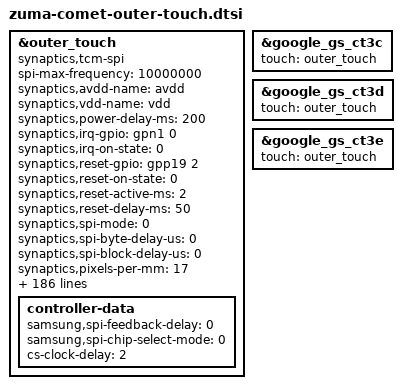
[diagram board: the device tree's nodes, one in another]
// SPDX-License-Identifier: GPL-2.0-only
/*
 * Google Comet touch device tree source
 *
 * Copyright 2023 Google LLC.
 *
 */

#include "zuma-comet-outer-common-touch.dtsi"

&outer_touch {
	status = "ok";
	compatible = "synaptics,tcm-spi";

	spi-max-frequency = <10000000>;

	synaptics,avdd-name = "avdd";
	synaptics,vdd-name = "vdd";
	synaptics,power-delay-ms = <200>;
	synaptics,irq-gpio = <&gpn1 0 0x2008>; /* IRQF_ONESHOT | IRQF_TRIGGER_LOW */
	synaptics,irq-on-state = <0>;
	synaptics,reset-gpio = <&gpp19 2 0>;
	synaptics,reset-on-state = <0>;
	synaptics,reset-active-ms = <2>;
	synaptics,reset-delay-ms = <50>;
	synaptics,spi-mode = <0>;
	synaptics,spi-byte-delay-us = <0>;
	synaptics,spi-block-delay-us = <0>;

	synaptics,pixels-per-mm = <17>;
	synaptics,panel_map = <&google_gs_ct3c 0>,<&google_gs_ct3d 1>,<&google_gs_ct3e 2>;
	synaptics,firmware_names = "synaptics.img","synaptics_b.img","synaptics_c.img";
	synaptics,test_algo = <0 1>;

	goog,panel_map = <&google_gs_ct3c 0>,<&google_gs_ct3d 1>,<&google_gs_ct3e 2>;

	goog,dev-id = <1>;
	goog,offload-device-name = "outer";
	goog,touch_offload_ids = /bits/ 8 <'c' 't' '3' '2' 'c' 't' '3' '3' 'c' 't' '3' '4'>;
	goog,display-resolution = /bits/ 16 <1080 2424>;
	goog,channel-num = /bits/ 16 <16 36>;
	goog,offload-caps-data-types = /bits/ 16 <0x1F>;
	goog,offload-caps-scan-types = /bits/ 16 <0xC0>;
	goog,offload-caps-context-channel-types = /bits/ 16 <0x0100>;
	goog,offload-caps-coord-filter;
	goog,tbn-enabled;
	goog,manual-heatmap-from-irq;
	goog,v4l2-enabled;
	goog,offload-enabled;
	goog,coord-filter-enabled;
	goog,reset-after-selftest;

	synaptics,pt05_high_name = "synaptics,pt05_high","synaptics,pt05_high_b",
			"synaptics,pt05_high_c";
	synaptics,pt05_low_name = "synaptics,pt05_low","synaptics,pt05_low_b",
			"synaptics,pt05_low_c";
	synaptics,pt05_gap_x_name = "synaptics,pt05_gap_x","synaptics,pt05_gap_x_b",
			"synaptics,pt05_gap_x_c";
	synaptics,pt05_gap_y_name = "synaptics,pt05_gap_y","synaptics,pt05_gap_y_b",
			"synaptics,pt05_gap_y_c";
	synaptics,pt0a_high_name = "synaptics,pt0a_high","synaptics,pt0a_high_b",
			"synaptics,pt0a_high_c";
	synaptics,pt0a_low_name = "synaptics,pt0a_low","synaptics,pt0a_low_b",
			"synaptics,pt0a_low_c";
	synaptics,pt10_high_name = "synaptics,pt10_high","synaptics,pt10_high_b",
			"synaptics,pt10_high_c";
	synaptics,pt10_low_name = "synaptics,pt10_low","synaptics,pt10_low_b",
			"synaptics,pt10_low_c";
	synaptics,pt10_gap_x_name = "synaptics,pt10_gap_x","synaptics,pt10_gap_x_b",
			"synaptics,pt10_gap_x_c";
	synaptics,pt10_gap_y_name = "synaptics,pt10_gap_y","synaptics,pt10_gap_y_b",
			"synaptics,pt10_gap_y_c";
	synaptics,pt11_high_name = "synaptics,pt11_high","synaptics,pt11_high_b",
			"synaptics,pt11_high";
	synaptics,pt11_low_name = "synaptics,pt11_low","synaptics,pt11_low_b",
			"synaptics,pt11_low_c";
	synaptics,pt12_high_name = "synaptics,pt12_high","synaptics,pt12_high_b",
			"synaptics,pt12_high_c";
	synaptics,pt12_low_name = "synaptics,pt12_low","synaptics,pt12_low_b",
			"synaptics,pt12_low_c";
	synaptics,pt16_high_name = "synaptics,pt16_high","synaptics,pt16_high_b",
			"synaptics,pt16_high_c";
	synaptics,pt16_low_name = "synaptics,pt16_low","synaptics,pt16_low_b",
			"synaptics,pt16_low_c";
	synaptics,pt_tag_moisture_name = "synaptics,pt_tag_moisture",
			"synaptics,pt_tag_moisture_b",
			"synaptics,pt_tag_moisture_c";

	synaptics,pt05_high = /bits/ 16 <
850 850 850 850 850 850 850 850 850 850 850 850 850 850 850 850 850 850 850 850 850 850 850 850 850 850 850 850 850 850 850 850 850 850 850 850
850 850 850 850 850 850 850 850 850 850 850 850 850 850 850 850 850 850 850 850 850 850 850 850 850 850 850 850 850 850 850 850 850 850 850 850
850 850 850 850 850 850 850 850 850 850 850 850 850 850 850 850 850 850 850 850 850 850 850 850 850 850 850 850 850 850 850 850 850 850 850 850
850 850 850 850 850 850 850 850 850 850 850 850 850 850 850 850 850 850 850 850 850 850 850 850 850 850 850 850 850 850 850 850 850 850 850 850
850 850 850 850 850 850 850 850 850 850 850 850 850 850 850 850 850 850 850 850 850 850 850 850 850 850 850 850 850 850 850 850 850 850 850 850
850 850 850 850 850 850 850 850 850 850 850 850 850 850 850 850 850 850 850 850 850 850 850 850 850 850 850 850 850 850 850 850 850 850 850 850
850 850 850 850 850 850 850 850 850 850 850 850 850 850 850 850 850 850 850 850 850 850 850 850 850 850 850 850 850 850 850 850 850 850 850 850
850 850 850 850 850 850 850 850 850 850 850 850 850 850 850 850 850 850 850 850 850 850 850 850 850 850 850 850 850 850 850 850 850 850 850 850
850 850 850 850 850 850 850 850 850 850 850 850 850 850 850 850 850 850 850 850 850 850 850 850 850 850 850 850 850 850 850 850 850 850 850 850
850 850 850 850 850 850 850 850 850 850 850 850 850 850 850 850 850 850 850 850 850 850 850 850 850 850 850 850 850 850 850 850 850 850 850 850
850 850 850 850 850 850 850 850 850 850 850 850 850 850 850 850 850 850 850 850 850 850 850 850 850 850 850 850 850 850 850 850 850 850 850 850
850 850 850 850 850 850 850 850 850 850 850 850 850 850 850 850 850 850 850 850 850 850 850 850 850 850 850 850 850 850 850 850 850 850 850 850
850 850 850 850 850 850 850 850 850 850 850 850 850 850 850 850 850 850 850 850 850 850 850 850 850 850 850 850 850 850 850 850 850 850 850 850
850 850 850 850 850 850 850 850 850 850 850 850 850 850 850 850 850 850 850 850 850 850 850 850 850 850 850 850 850 850 850 850 850 850 850 850
850 850 850 850 850 850 850 850 850 850 850 850 850 850 850 850 850 850 850 850 850 850 850 850 850 850 850 850 850 850 850 850 850 850 850 850
850 850 850 850 850 850 850 850 850 850 850 850 850 850 850 850 850 850 850 850 850 850 850 850 850 850 850 850 850 850 850 850 850 850 850 850>;
	synaptics,pt05_low = /bits/ 16 <
80 100 100 100 100 100 100 100 100 100 100 100 100 100 100 100 100 100 100 100 100 100 100 100 100 100 100 100 100 100 100 100 100 100 100 15
100 100 100 100 100 100 100 100 100 100 100 100 100 100 100 100 100 100 100 100 100 100 100 100 100 100 100 100 100 100 100 100 100 100 100 100
100 100 100 100 100 100 100 100 100 100 100 100 100 100 100 100 100 100 100 100 100 100 100 100 100 100 100 100 100 100 100 100 100 100 100 100
100 100 100 100 100 100 100 100 100 100 100 100 100 100 100 100 100 100 100 100 100 100 100 100 100 100 100 100 100 100 100 100 100 100 100 100
100 100 100 100 100 100 100 100 100 100 100 100 100 100 100 100 100 100 100 100 100 100 100 100 100 100 100 100 100 100 100 100 100 100 100 100
100 100 100 100 100 100 100 100 100 100 100 100 100 100 100 100 100 100 100 100 100 100 100 100 100 100 100 100 100 100 100 100 100 100 100 100
100 100 100 100 100 100 100 100 100 100 100 100 100 100 100 100 100 100 100 100 100 100 100 100 100 100 100 100 100 100 100 100 100 100 100 100
100 100 100 100 100 100 100 100 100 100 100 100 100 100 100 100 100 100 100 100 100 100 100 100 100 100 100 100 100 100 100 100 100 100 100 100
100 100 100 100 100 100 100 100 100 100 100 100 100 100 100 100 100 100 100 100 100 100 100 100 100 100 100 100 100 100 100 100 100 100 100 100
100 100 100 100 100 100 100 100 100 100 100 100 100 100 100 100 100 100 100 100 100 100 100 100 100 100 100 100 100 100 100 100 100 100 100 100
100 100 100 100 100 100 100 100 100 100 100 100 100 100 100 100 100 100 100 100 100 100 100 100 100 100 100 100 100 100 100 100 100 100 100 100
100 100 100 100 100 100 100 100 100 100 100 100 100 100 100 100 100 100 100 100 100 100 100 100 100 100 100 100 100 100 100 100 100 100 100 100
100 100 100 100 100 100 100 100 100 100 100 100 100 100 100 100 100 100 100 100 100 100 100 100 100 100 100 100 100 100 100 100 100 100 100 100
100 100 100 100 100 100 100 100 100 100 100 100 100 100 100 100 100 100 100 100 100 100 100 100 100 100 100 100 100 100 100 100 100 100 100 100
100 100 100 100 100 100 100 100 100 100 100 100 100 100 100 100 100 100 100 100 100 100 100 100 100 100 100 100 100 100 100 100 100 100 100 100
15 100 100 100 100 100 100 100 100 100 100 100 100 100 100 100 100 100 100 100 100 100 100 100 100 100 100 100 100 100 100 100 100 100 100 80>;
	synaptics,pt05_gap_x = /bits/ 16 <
97 60 40 40 40 40 40 40 40 40 40 40 40 40 40 40 40 40 40 40 40 40 40 40 40 40 40 40 40 40 40 40 40 40 97 97
60 40 40 40 40 40 40 40 40 40 40 40 40 40 40 40 40 40 40 40 40 40 40 40 40 40 40 40 40 40 40 40 40 40 50 60
40 40 40 40 40 40 40 40 40 40 40 40 40 40 40 40 40 40 40 40 40 40 40 40 40 40 40 40 40 40 40 40 40 40 50 40
40 40 40 40 40 40 40 40 40 40 40 40 40 40 40 40 40 40 40 40 40 40 40 40 40 40 40 40 40 40 40 40 40 40 50 40
40 40 40 40 40 40 40 40 40 40 40 40 40 40 40 40 40 40 40 40 40 40 40 40 40 40 40 40 40 40 40 40 40 40 50 40
40 40 40 40 40 40 40 40 40 40 40 40 40 40 40 40 40 40 40 40 40 40 40 40 40 40 40 40 40 40 40 40 40 40 50 40
40 55 40 40 40 40 40 40 40 40 40 40 40 40 40 40 40 40 40 40 40 40 40 40 40 40 40 40 40 40 40 40 40 40 50 40
55 55 40 40 40 40 40 40 40 40 40 40 40 40 40 40 40 40 40 40 40 40 40 40 40 40 40 40 40 40 40 40 40 40 50 40
55 55 40 40 40 40 40 40 40 40 40 40 40 40 40 40 40 40 40 40 40 40 40 40 40 40 40 40 40 40 40 40 40 40 50 40
40 40 40 40 40 40 40 40 40 40 40 40 40 40 40 40 40 40 40 40 40 40 40 40 40 40 40 40 40 40 40 40 40 40 50 40
40 40 40 40 40 40 40 40 40 40 40 40 40 40 40 40 40 40 40 40 40 40 40 40 40 40 40 40 40 40 40 40 40 40 50 40
40 40 40 40 40 40 40 40 40 40 40 40 40 40 40 40 40 40 40 40 40 40 40 40 40 40 40 40 40 40 40 40 40 40 50 40
40 40 40 40 40 40 40 40 40 40 40 40 40 40 40 40 40 40 40 40 40 40 40 40 40 40 40 40 40 40 40 40 40 40 50 40
60 40 40 40 40 40 40 40 40 40 40 40 40 40 40 40 40 40 40 40 40 40 40 40 40 40 40 40 40 40 40 40 40 40 50 60
97 60 40 40 40 40 40 40 40 40 40 40 40 40 40 40 40 40 40 40 40 40 40 40 40 40 40 40 40 40 40 40 40 40 60 60
97 60 40 40 40 40 40 40 40 40 40 40 40 40 40 40 40 40 40 40 40 40 40 40 40 40 40 40 40 40 40 40 40 40 97 40>;

	synaptics,pt0a_high = /bits/ 16 <
50 50 50 50 50 50 50 50 50 50 50 50 50 50 50 50 50 50 50 50 50 50 50 50 50 50 50 50 50 50 50 50 50 50 50 50
50 50 50 50 50 50 50 50 50 50 50 50 50 50 50 50 50 50 50 50 50 50 50 50 50 50 50 50 50 50 50 50 50 50 50 50
50 50 50 50 50 50 50 50 50 50 50 50 50 50 50 50 50 50 50 50 50 50 50 50 50 50 50 50 50 50 50 50 50 50 50 50
50 50 50 50 50 50 50 50 50 50 50 50 50 50 50 50 50 50 50 50 50 50 50 50 50 50 50 50 50 50 50 50 50 50 50 50
50 50 50 50 50 50 50 50 50 50 50 50 50 50 50 50 50 50 50 50 50 50 50 50 50 50 50 50 50 50 50 50 50 50 50 50
50 50 50 50 50 50 50 50 50 50 50 50 50 50 50 50 50 50 50 50 50 50 50 50 50 50 50 50 50 50 50 50 50 50 50 50
50 50 50 50 50 50 50 50 50 50 50 50 50 50 50 50 50 50 50 50 50 50 50 50 50 50 50 50 50 50 50 50 50 50 50 50
50 50 50 50 50 50 50 50 50 50 50 50 50 50 50 50 50 50 50 50 50 50 50 50 50 50 50 50 50 50 50 50 50 50 50 50
50 50 50 50 50 50 50 50 50 50 50 50 50 50 50 50 50 50 50 50 50 50 50 50 50 50 50 50 50 50 50 50 50 50 50 50
50 50 50 50 50 50 50 50 50 50 50 50 50 50 50 50 50 50 50 50 50 50 50 50 50 50 50 50 50 50 50 50 50 50 50 50
50 50 50 50 50 50 50 50 50 50 50 50 50 50 50 50 50 50 50 50 50 50 50 50 50 50 50 50 50 50 50 50 50 50 50 50
50 50 50 50 50 50 50 50 50 50 50 50 50 50 50 50 50 50 50 50 50 50 50 50 50 50 50 50 50 50 50 50 50 50 50 50
50 50 50 50 50 50 50 50 50 50 50 50 50 50 50 50 50 50 50 50 50 50 50 50 50 50 50 50 50 50 50 50 50 50 50 50
50 50 50 50 50 50 50 50 50 50 50 50 50 50 50 50 50 50 50 50 50 50 50 50 50 50 50 50 50 50 50 50 50 50 50 50
50 50 50 50 50 50 50 50 50 50 50 50 50 50 50 50 50 50 50 50 50 50 50 50 50 50 50 50 50 50 50 50 50 50 50 50
50 50 50 50 50 50 50 50 50 50 50 50 50 50 50 50 50 50 50 50 50 50 50 50 50 50 50 50 50 50 50 50 50 50 50 50>;
	synaptics,pt0a_low = /bits/ 16 <
(-50) (-50) (-50) (-50) (-50) (-50) (-50) (-50) (-50) (-50) (-50) (-50) (-50) (-50) (-50) (-50) (-50) (-50) (-50) (-50) (-50) (-50) (-50) (-50) (-50) (-50) (-50) (-50) (-50) (-50) (-50) (-50) (-50) (-50) (-50) (-50)
(-50) (-50) (-50) (-50) (-50) (-50) (-50) (-50) (-50) (-50) (-50) (-50) (-50) (-50) (-50) (-50) (-50) (-50) (-50) (-50) (-50) (-50) (-50) (-50) (-50) (-50) (-50) (-50) (-50) (-50) (-50) (-50) (-50) (-50) (-50) (-50)
(-50) (-50) (-50) (-50) (-50) (-50) (-50) (-50) (-50) (-50) (-50) (-50) (-50) (-50) (-50) (-50) (-50) (-50) (-50) (-50) (-50) (-50) (-50) (-50) (-50) (-50) (-50) (-50) (-50) (-50) (-50) (-50) (-50) (-50) (-50) (-50)
(-50) (-50) (-50) (-50) (-50) (-50) (-50) (-50) (-50) (-50) (-50) (-50) (-50) (-50) (-50) (-50) (-50) (-50) (-50) (-50) (-50) (-50) (-50) (-50) (-50) (-50) (-50) (-50) (-50) (-50) (-50) (-50) (-50) (-50) (-50) (-50)
(-50) (-50) (-50) (-50) (-50) (-50) (-50) (-50) (-50) (-50) (-50) (-50) (-50) (-50) (-50) (-50) (-50) (-50) (-50) (-50) (-50) (-50) (-50) (-50) (-50) (-50) (-50) (-50) (-50) (-50) (-50) (-50) (-50) (-50) (-50) (-50)
(-50) (-50) (-50) (-50) (-50) (-50) (-50) (-50) (-50) (-50) (-50) (-50) (-50) (-50) (-50) (-50) (-50) (-50) (-50) (-50) (-50) (-50) (-50) (-50) (-50) (-50) (-50) (-50) (-50) (-50) (-50) (-50) (-50) (-50) (-50) (-50)
(-50) (-50) (-50) (-50) (-50) (-50) (-50) (-50) (-50) (-50) (-50) (-50) (-50) (-50) (-50) (-50) (-50) (-50) (-50) (-50) (-50) (-50) (-50) (-50) (-50) (-50) (-50) (-50) (-50) (-50) (-50) (-50) (-50) (-50) (-50) (-50)
(-50) (-50) (-50) (-50) (-50) (-50) (-50) (-50) (-50) (-50) (-50) (-50) (-50) (-50) (-50) (-50) (-50) (-50) (-50) (-50) (-50) (-50) (-50) (-50) (-50) (-50) (-50) (-50) (-50) (-50) (-50) (-50) (-50) (-50) (-50) (-50)
(-50) (-50) (-50) (-50) (-50) (-50) (-50) (-50) (-50) (-50) (-50) (-50) (-50) (-50) (-50) (-50) (-50) (-50) (-50) (-50) (-50) (-50) (-50) (-50) (-50) (-50) (-50) (-50) (-50) (-50) (-50) (-50) (-50) (-50) (-50) (-50)
(-50) (-50) (-50) (-50) (-50) (-50) (-50) (-50) (-50) (-50) (-50) (-50) (-50) (-50) (-50) (-50) (-50) (-50) (-50) (-50) (-50) (-50) (-50) (-50) (-50) (-50) (-50) (-50) (-50) (-50) (-50) (-50) (-50) (-50) (-50) (-50)
(-50) (-50) (-50) (-50) (-50) (-50) (-50) (-50) (-50) (-50) (-50) (-50) (-50) (-50) (-50) (-50) (-50) (-50) (-50) (-50) (-50) (-50) (-50) (-50) (-50) (-50) (-50) (-50) (-50) (-50) (-50) (-50) (-50) (-50) (-50) (-50)
(-50) (-50) (-50) (-50) (-50) (-50) (-50) (-50) (-50) (-50) (-50) (-50) (-50) (-50) (-50) (-50) (-50) (-50) (-50) (-50) (-50) (-50) (-50) (-50) (-50) (-50) (-50) (-50) (-50) (-50) (-50) (-50) (-50) (-50) (-50) (-50)
(-50) (-50) (-50) (-50) (-50) (-50) (-50) (-50) (-50) (-50) (-50) (-50) (-50) (-50) (-50) (-50) (-50) (-50) (-50) (-50) (-50) (-50) (-50) (-50) (-50) (-50) (-50) (-50) (-50) (-50) (-50) (-50) (-50) (-50) (-50) (-50)
(-50) (-50) (-50) (-50) (-50) (-50) (-50) (-50) (-50) (-50) (-50) (-50) (-50) (-50) (-50) (-50) (-50) (-50) (-50) (-50) (-50) (-50) (-50) (-50) (-50) (-50) (-50) (-50) (-50) (-50) (-50) (-50) (-50) (-50) (-50) (-50)
(-50) (-50) (-50) (-50) (-50) (-50) (-50) (-50) (-50) (-50) (-50) (-50) (-50) (-50) (-50) (-50) (-50) (-50) (-50) (-50) (-50) (-50) (-50) (-50) (-50) (-50) (-50) (-50) (-50) (-50) (-50) (-50) (-50) (-50) (-50) (-50)
(-50) (-50) (-50) (-50) (-50) (-50) (-50) (-50) (-50) (-50) (-50) (-50) (-50) (-50) (-50) (-50) (-50) (-50) (-50) (-50) (-50) (-50) (-50) (-50) (-50) (-50) (-50) (-50) (-50) (-50) (-50) (-50) (-50) (-50) (-50) (-50)>;

	synaptics,pt10_high = /bits/ 16 <
55 55 55 55 55 55 55 55 55 55 55 55 55 55 55 55 55 55 55 55 55 55 55 55 55 55 55 55 55 55 55 55 55 55 55 55
55 55 55 55 55 55 55 55 55 55 55 55 55 55 55 55 55 55 55 55 55 55 55 55 55 55 55 55 55 55 55 55 55 55 55 55
55 55 55 55 55 55 55 55 55 55 55 55 55 55 55 55 55 55 55 55 55 55 55 55 55 55 55 55 55 55 55 55 55 55 55 55
55 55 55 55 55 55 55 55 55 55 55 55 55 55 55 55 55 55 55 55 55 55 55 55 55 55 55 55 55 55 55 55 55 55 55 55
55 55 55 55 55 55 55 55 55 55 55 55 55 55 55 55 55 55 55 55 55 55 55 55 55 55 55 55 55 55 55 55 55 55 55 55
55 55 55 55 55 55 55 55 55 55 55 55 55 55 55 55 55 55 55 55 55 55 55 55 55 55 55 55 55 55 55 55 55 55 55 55
55 55 55 55 55 55 55 55 55 55 55 55 55 55 55 55 55 55 55 55 55 55 55 55 55 55 55 55 55 55 55 55 55 55 55 55
55 55 55 55 55 55 55 55 55 55 55 55 55 55 55 55 55 55 55 55 55 55 55 55 55 55 55 55 55 55 55 55 55 55 55 55
55 55 55 55 55 55 55 55 55 55 55 55 55 55 55 55 55 55 55 55 55 55 55 55 55 55 55 55 55 55 55 55 55 55 55 55
55 55 55 55 55 55 55 55 55 55 55 55 55 55 55 55 55 55 55 55 55 55 55 55 55 55 55 55 55 55 55 55 55 55 55 55
55 55 55 55 55 55 55 55 55 55 55 55 55 55 55 55 55 55 55 55 55 55 55 55 55 55 55 55 55 55 55 55 55 55 55 55
55 55 55 55 55 55 55 55 55 55 55 55 55 55 55 55 55 55 55 55 55 55 55 55 55 55 55 55 55 55 55 55 55 55 55 55
55 55 55 55 55 55 55 55 55 55 55 55 55 55 55 55 55 55 55 55 55 55 55 55 55 55 55 55 55 55 55 55 55 55 55 55
55 55 55 55 55 55 55 55 55 55 55 55 55 55 55 55 55 55 55 55 55 55 55 55 55 55 55 55 55 55 55 55 55 55 55 55
55 55 55 55 55 55 55 55 55 55 55 55 55 55 55 55 55 55 55 55 55 55 55 55 55 55 55 55 55 55 55 55 55 55 55 55
55 55 55 55 55 55 55 55 55 55 55 55 55 55 55 55 55 55 55 55 55 55 55 55 55 55 55 55 55 55 55 55 55 55 55 55>;
	synaptics,pt10_low = /bits/ 16 <
0 0 0 0 0 0 0 0 0 0 0 0 0 0 0 0 0 0 0 0 0 0 0 0 0 0 0 0 0 0 0 0 0 0 0 0
0 0 0 0 0 0 0 0 0 0 0 0 0 0 0 0 0 0 0 0 0 0 0 0 0 0 0 0 0 0 0 0 0 0 0 0
0 0 0 0 0 0 0 0 0 0 0 0 0 0 0 0 0 0 0 0 0 0 0 0 0 0 0 0 0 0 0 0 0 0 0 0
0 0 0 0 0 0 0 0 0 0 0 0 0 0 0 0 0 0 0 0 0 0 0 0 0 0 0 0 0 0 0 0 0 0 0 0
0 0 0 0 0 0 0 0 0 0 0 0 0 0 0 0 0 0 0 0 0 0 0 0 0 0 0 0 0 0 0 0 0 0 0 0
0 0 0 0 0 0 0 0 0 0 0 0 0 0 0 0 0 0 0 0 0 0 0 0 0 0 0 0 0 0 0 0 0 0 0 0
0 0 0 0 0 0 0 0 0 0 0 0 0 0 0 0 0 0 0 0 0 0 0 0 0 0 0 0 0 0 0 0 0 0 0 0
0 0 0 0 0 0 0 0 0 0 0 0 0 0 0 0 0 0 0 0 0 0 0 0 0 0 0 0 0 0 0 0 0 0 0 0
0 0 0 0 0 0 0 0 0 0 0 0 0 0 0 0 0 0 0 0 0 0 0 0 0 0 0 0 0 0 0 0 0 0 0 0
0 0 0 0 0 0 0 0 0 0 0 0 0 0 0 0 0 0 0 0 0 0 0 0 0 0 0 0 0 0 0 0 0 0 0 0
0 0 0 0 0 0 0 0 0 0 0 0 0 0 0 0 0 0 0 0 0 0 0 0 0 0 0 0 0 0 0 0 0 0 0 0
0 0 0 0 0 0 0 0 0 0 0 0 0 0 0 0 0 0 0 0 0 0 0 0 0 0 0 0 0 0 0 0 0 0 0 0
0 0 0 0 0 0 0 0 0 0 0 0 0 0 0 0 0 0 0 0 0 0 0 0 0 0 0 0 0 0 0 0 0 0 0 0
0 0 0 0 0 0 0 0 0 0 0 0 0 0 0 0 0 0 0 0 0 0 0 0 0 0 0 0 0 0 0 0 0 0 0 0
0 0 0 0 0 0 0 0 0 0 0 0 0 0 0 0 0 0 0 0 0 0 0 0 0 0 0 0 0 0 0 0 0 0 0 0
0 0 0 0 0 0 0 0 0 0 0 0 0 0 0 0 0 0 0 0 0 0 0 0 0 0 0 0 0 0 0 0 0 0 0 0>;
	synaptics,pt10_gap_x = /bits/ 16 <
50 50 50 50 50 50 50 50 50 50 50 50 50 50 50 50 50 50 50 50 50 50 50 50 50 50 50 50 50 50 50 50 50 50 50 50
50 50 50 50 50 50 50 50 50 50 50 50 50 50 50 50 50 50 50 50 50 50 50 50 50 50 50 50 50 50 50 50 50 50 50 50
50 50 50 50 50 50 50 50 50 50 50 50 50 50 50 50 50 50 50 50 50 50 50 50 50 50 50 50 50 50 50 50 50 50 50 50
50 50 50 50 50 50 50 50 50 50 50 50 50 50 50 50 50 50 50 50 50 50 50 50 50 50 50 50 50 50 50 50 50 50 50 50
50 50 50 50 50 50 50 50 50 50 50 50 50 50 50 50 50 50 50 50 50 50 50 50 50 50 50 50 50 50 50 50 50 50 50 50
50 50 50 50 50 50 50 50 50 50 50 50 50 50 50 50 50 50 50 50 50 50 50 50 50 50 50 50 50 50 50 50 50 50 50 50
50 50 50 50 50 50 50 50 50 50 50 50 50 50 50 50 50 50 50 50 50 50 50 50 50 50 50 50 50 50 50 50 50 50 50 50
50 50 50 50 50 50 50 50 50 50 50 50 50 50 50 50 50 50 50 50 50 50 50 50 50 50 50 50 50 50 50 50 50 50 50 50
50 50 50 50 50 50 50 50 50 50 50 50 50 50 50 50 50 50 50 50 50 50 50 50 50 50 50 50 50 50 50 50 50 50 50 50
50 50 50 50 50 50 50 50 50 50 50 50 50 50 50 50 50 50 50 50 50 50 50 50 50 50 50 50 50 50 50 50 50 50 50 50
50 50 50 50 50 50 50 50 50 50 50 50 50 50 50 50 50 50 50 50 50 50 50 50 50 50 50 50 50 50 50 50 50 50 50 50
50 50 50 50 50 50 50 50 50 50 50 50 50 50 50 50 50 50 50 50 50 50 50 50 50 50 50 50 50 50 50 50 50 50 50 50
50 50 50 50 50 50 50 50 50 50 50 50 50 50 50 50 50 50 50 50 50 50 50 50 50 50 50 50 50 50 50 50 50 50 50 50
50 50 50 50 50 50 50 50 50 50 50 50 50 50 50 50 50 50 50 50 50 50 50 50 50 50 50 50 50 50 50 50 50 50 50 50
50 50 50 50 50 50 50 50 50 50 50 50 50 50 50 50 50 50 50 50 50 50 50 50 50 50 50 50 50 50 50 50 50 50 50 50
50 50 50 50 50 50 50 50 50 50 50 50 50 50 50 50 50 50 50 50 50 50 50 50 50 50 50 50 50 50 50 50 50 50 50 50>;

	synaptics,pt11_high = /bits/ 16 <
200 200 200 200 200 200 200 200 200 200 200 200 200 200 200 200 200 200 200 200 200 200 200 200 200 200 200 200 200 200 200 200 200 200 200 200
200 200 200 200 200 200 200 200 200 200 200 200 200 200 200 200 200 200 200 200 200 200 200 200 200 200 200 200 200 200 200 200 200 200 200 200
200 200 200 200 200 200 200 200 200 200 200 200 200 200 200 200 200 200 200 200 200 200 200 200 200 200 200 200 200 200 200 200 200 200 200 200
200 200 200 200 200 200 200 200 200 200 200 200 200 200 200 200 200 200 200 200 200 200 200 200 200 200 200 200 200 200 200 200 200 200 200 200
200 200 200 200 200 200 200 200 200 200 200 200 200 200 200 200 200 200 200 200 200 200 200 200 200 200 200 200 200 200 200 200 200 200 200 200
200 200 200 200 200 200 200 200 200 200 200 200 200 200 200 200 200 200 200 200 200 200 200 200 200 200 200 200 200 200 200 200 200 200 200 200
200 200 200 200 200 200 200 200 200 200 200 200 200 200 200 200 200 200 200 200 200 200 200 200 200 200 200 200 200 200 200 200 200 200 200 200
200 200 200 200 200 200 200 200 200 200 200 200 200 200 200 200 200 200 200 200 200 200 200 200 200 200 200 200 200 200 200 200 200 200 200 200
200 200 200 200 200 200 200 200 200 200 200 200 200 200 200 200 200 200 200 200 200 200 200 200 200 200 200 200 200 200 200 200 200 200 200 200
200 200 200 200 200 200 200 200 200 200 200 200 200 200 200 200 200 200 200 200 200 200 200 200 200 200 200 200 200 200 200 200 200 200 200 200
200 200 200 200 200 200 200 200 200 200 200 200 200 200 200 200 200 200 200 200 200 200 200 200 200 200 200 200 200 200 200 200 200 200 200 200
200 200 200 200 200 200 200 200 200 200 200 200 200 200 200 200 200 200 200 200 200 200 200 200 200 200 200 200 200 200 200 200 200 200 200 200
200 200 200 200 200 200 200 200 200 200 200 200 200 200 200 200 200 200 200 200 200 200 200 200 200 200 200 200 200 200 200 200 200 200 200 200
200 200 200 200 200 200 200 200 200 200 200 200 200 200 200 200 200 200 200 200 200 200 200 200 200 200 200 200 200 200 200 200 200 200 200 200
200 200 200 200 200 200 200 200 200 200 200 200 200 200 200 200 200 200 200 200 200 200 200 200 200 200 200 200 200 200 200 200 200 200 200 200
200 200 200 200 200 200 200 200 200 200 200 200 200 200 200 200 200 200 200 200 200 200 200 200 200 200 200 200 200 200 200 200 200 200 200 200>;
	synaptics,pt11_low = /bits/ 16 <
70 70 70 70 70 70 70 70 70 70 70 70 70 70 70 70 70 70 70 70 70 70 70 70 70 70 70 70 70 70 70 70 70 70 70 70
70 70 70 70 70 70 70 70 70 70 70 70 70 70 70 70 70 70 70 70 70 70 70 70 70 70 70 70 70 70 70 70 70 70 70 70
70 70 70 70 70 70 70 70 70 70 70 70 70 70 70 70 70 70 70 70 70 70 70 70 70 70 70 70 70 70 70 70 70 70 70 70
70 70 70 70 70 70 70 70 70 70 70 70 70 70 70 70 70 70 70 70 70 70 70 70 70 70 70 70 70 70 70 70 70 70 70 70
70 70 70 70 70 70 70 70 70 70 70 70 70 70 70 70 70 70 70 70 70 70 70 70 70 70 70 70 70 70 70 70 70 70 70 70
70 70 70 70 70 70 70 70 70 70 70 70 70 70 70 70 70 70 70 70 70 70 70 70 70 70 70 70 70 70 70 70 70 70 70 70
70 70 70 70 70 70 70 70 70 70 70 70 70 70 70 70 70 70 70 70 70 70 70 70 70 70 70 70 70 70 70 70 70 70 70 70
70 70 70 70 70 70 70 70 70 70 70 70 70 70 70 70 70 70 70 70 70 70 70 70 70 70 70 70 70 70 70 70 70 70 70 70
70 70 70 70 70 70 70 70 70 70 70 70 70 70 70 70 70 70 70 70 70 70 70 70 70 70 70 70 70 70 70 70 70 70 70 70
70 70 70 70 70 70 70 70 70 70 70 70 70 70 70 70 70 70 70 70 70 70 70 70 70 70 70 70 70 70 70 70 70 70 70 70
70 70 70 70 70 70 70 70 70 70 70 70 70 70 70 70 70 70 70 70 70 70 70 70 70 70 70 70 70 70 70 70 70 70 70 70
70 70 70 70 70 70 70 70 70 70 70 70 70 70 70 70 70 70 70 70 70 70 70 70 70 70 70 70 70 70 70 70 70 70 70 70
70 70 70 70 70 70 70 70 70 70 70 70 70 70 70 70 70 70 70 70 70 70 70 70 70 70 70 70 70 70 70 70 70 70 70 70
70 70 70 70 70 70 70 70 70 70 70 70 70 70 70 70 70 70 70 70 70 70 70 70 70 70 70 70 70 70 70 70 70 70 70 70
70 70 70 70 70 70 70 70 70 70 70 70 70 70 70 70 70 70 70 70 70 70 70 70 70 70 70 70 70 70 70 70 70 70 70 70
70 70 70 70 70 70 70 70 70 70 70 70 70 70 70 70 70 70 70 70 70 70 70 70 70 70 70 70 70 70 70 70 70 70 70 70>;

	synaptics,pt12_high = <
320000 320000 320000 320000 320000 320000 320000 320000 320000 320000 320000 320000 320000 320000 320000 320000 320000 320000 320000 320000 320000 320000 320000 320000 320000 320000 320000 320000 320000 320000 320000 320000 320000 320000 320000 320000 460000 460000 460000 460000 400000 460000 460000 460000 460000 460000 460000 460000 460000 460000 460000 460000>;
	synaptics,pt12_low = <
180000 180000 180000 180000 180000 180000 180000 180000 180000 180000 180000 180000 180000 180000 180000 180000 180000 180000 180000 180000 180000 180000 180000 180000 180000 180000 180000 180000 180000 180000 180000 180000 180000 180000 180000 180000 180000 260000 260000 260000 260000 260000 260000 260000 260000 260000 260000 260000 260000 260000 260000 260000>;

	synaptics,pt16_high = /bits/ 16 <
950 950 950 950 950 950 950 950 950 950 950 950 950 950 950 950 950 950 950 950 950 950 950 950 950 950 950 950 950 950 950 950 950 950 950 950
950 950 950 950 950 950 950 950 950 950 950 950 950 950 950 950 950 950 950 950 950 950 950 950 950 950 950 950 950 950 950 950 950 950 950 950
950 950 950 950 950 950 950 950 950 950 950 950 950 950 950 950 950 950 950 950 950 950 950 950 950 950 950 950 950 950 950 950 950 950 950 950
950 950 950 950 950 950 950 950 950 950 950 950 950 950 950 950 950 950 950 950 950 950 950 950 950 950 950 950 950 950 950 950 950 950 950 950
950 950 950 950 950 950 950 950 950 950 950 950 950 950 950 950 950 950 950 950 950 950 950 950 950 950 950 950 950 950 950 950 950 950 950 950
950 950 950 950 950 950 950 950 950 950 950 950 950 950 950 950 950 950 950 950 950 950 950 950 950 950 950 950 950 950 950 950 950 950 950 950
950 950 950 950 950 950 950 950 950 950 950 950 950 950 950 950 950 950 950 950 950 950 950 950 950 950 950 950 950 950 950 950 950 950 950 950
950 950 950 950 950 950 950 950 950 950 950 950 950 950 950 950 950 950 950 950 950 950 950 950 950 950 950 950 950 950 950 950 950 950 950 950
950 950 950 950 950 950 950 950 950 950 950 950 950 950 950 950 950 950 950 950 950 950 950 950 950 950 950 950 950 950 950 950 950 950 950 950
950 950 950 950 950 950 950 950 950 950 950 950 950 950 950 950 950 950 950 950 950 950 950 950 950 950 950 950 950 950 950 950 950 950 950 950
950 950 950 950 950 950 950 950 950 950 950 950 950 950 950 950 950 950 950 950 950 950 950 950 950 950 950 950 950 950 950 950 950 950 950 950
950 950 950 950 950 950 950 950 950 950 950 950 950 950 950 950 950 950 950 950 950 950 950 950 950 950 950 950 950 950 950 950 950 950 950 950
950 950 950 950 950 950 950 950 950 950 950 950 950 950 950 950 950 950 950 950 950 950 950 950 950 950 950 950 950 950 950 950 950 950 950 950
950 950 950 950 950 950 950 950 950 950 950 950 950 950 950 950 950 950 950 950 950 950 950 950 950 950 950 950 950 950 950 950 950 950 950 950
950 950 950 950 950 950 950 950 950 950 950 950 950 950 950 950 950 950 950 950 950 950 950 950 950 950 950 950 950 950 950 950 950 950 950 950
950 950 950 950 950 950 950 950 950 950 950 950 950 950 950 950 950 950 950 950 950 950 950 950 950 950 950 950 950 950 950 950 950 950 950 950>;
	synaptics,pt16_low = /bits/ 16 <
90 100 100 100 100 100 100 100 100 100 100 100 100 100 100 100 100 100 100 100 100 100 100 100 100 100 100 100 100 100 100 100 100 100 100 15
100 100 100 100 100 100 100 100 100 100 100 100 100 100 100 100 100 100 100 100 100 100 100 100 100 100 100 100 100 100 100 100 100 100 100 100
100 100 100 100 100 100 100 100 100 100 100 100 100 100 100 100 100 100 100 100 100 100 100 100 100 100 100 100 100 100 100 100 100 100 100 100
100 100 100 100 100 100 100 100 100 100 100 100 100 100 100 100 100 100 100 100 100 100 100 100 100 100 100 100 100 100 100 100 100 100 100 100
100 100 100 100 100 100 100 100 100 100 100 100 100 100 100 100 100 100 100 100 100 100 100 100 100 100 100 100 100 100 100 100 100 100 100 100
100 100 100 100 100 100 100 100 100 100 100 100 100 100 100 100 100 100 100 100 100 100 100 100 100 100 100 100 100 100 100 100 100 100 100 100
100 100 100 100 100 100 100 100 100 100 100 100 100 100 100 100 100 100 100 100 100 100 100 100 100 100 100 100 100 100 100 100 100 100 100 100
100 100 100 100 100 100 100 100 100 100 100 100 100 100 100 100 100 100 100 100 100 100 100 100 100 100 100 100 100 100 100 100 100 100 100 100
100 100 100 100 100 100 100 100 100 100 100 100 100 100 100 100 100 100 100 100 100 100 100 100 100 100 100 100 100 100 100 100 100 100 100 100
100 100 100 100 100 100 100 100 100 100 100 100 100 100 100 100 100 100 100 100 100 100 100 100 100 100 100 100 100 100 100 100 100 100 100 100
100 100 100 100 100 100 100 100 100 100 100 100 100 100 100 100 100 100 100 100 100 100 100 100 100 100 100 100 100 100 100 100 100 100 100 100
100 100 100 100 100 100 100 100 100 100 100 100 100 100 100 100 100 100 100 100 100 100 100 100 100 100 100 100 100 100 100 100 100 100 100 100
100 100 100 100 100 100 100 100 100 100 100 100 100 100 100 100 100 100 100 100 100 100 100 100 100 100 100 100 100 100 100 100 100 100 100 100
100 100 100 100 100 100 100 100 100 100 100 100 100 100 100 100 100 100 100 100 100 100 100 100 100 100 100 100 100 100 100 100 100 100 100 100
100 100 100 100 100 100 100 100 100 100 100 100 100 100 100 100 100 100 100 100 100 100 100 100 100 100 100 100 100 100 100 100 100 100 100 100
15 100 100 100 100 100 100 100 100 100 100 100 100 100 100 100 100 100 100 100 100 100 100 100 100 100 100 100 100 100 100 100 100 100 100 90>;

	synaptics,pt_tag_moisture = /bits/ 16 <
1000 1000 1000 1000 1000 1000 1000 1000 1000 1000 1000 1000 1000 1000 1000 1000 1000 1000 1000 1000 1000 1000 1000 1000 1000 1000 1000 1000 1000 1000 1000 1000 1000 1000 1000 0
1000 1000 1000 1000 1000 1000 1000 1000 1000 1000 1000 1000 1000 1000 1000 1000 1000 1000 1000 1000 1000 1000 1000 1000 1000 1000 1000 1000 1000 1000 1000 1000 1000 1000 1000 0
1000 1000 1000 1000 1000 1000 1000 1000 1000 1000 1000 1000 1000 1000 1000 1000 1000 1000 1000 1000 1000 1000 1000 1000 1000 1000 1000 1000 1000 1000 1000 1000 1000 1000 1000 0
1000 1000 1000 1000 1000 1000 1000 1000 1000 1000 1000 1000 1000 1000 1000 1000 1000 1000 1000 1000 1000 1000 1000 1000 1000 1000 1000 1000 1000 1000 1000 1000 1000 1000 1000 0
1000 1000 1000 1000 1000 1000 1000 1000 1000 1000 1000 1000 1000 1000 1000 1000 1000 1000 1000 1000 1000 1000 1000 1000 1000 1000 1000 1000 1000 1000 1000 1000 1000 1000 1000 0
1000 1000 1000 1000 1000 1000 1000 1000 1000 1000 1000 1000 1000 1000 1000 1000 1000 1000 1000 1000 1000 1000 1000 1000 1000 1000 1000 1000 1000 1000 1000 1000 1000 1000 1000 0
1000 1000 1000 1000 1000 1000 1000 1000 1000 1000 1000 1000 1000 1000 1000 1000 1000 1000 1000 1000 1000 1000 1000 1000 1000 1000 1000 1000 1000 1000 1000 1000 1000 1000 1000 0
1000 1000 1000 1000 1000 1000 1000 1000 1000 1000 1000 1000 1000 1000 1000 1000 1000 1000 1000 1000 1000 1000 1000 1000 1000 1000 1000 1000 1000 1000 1000 1000 1000 1000 1000 0
1000 1000 1000 1000 1000 1000 1000 1000 1000 1000 1000 1000 1000 1000 1000 1000 1000 1000 1000 1000 1000 1000 1000 1000 1000 1000 1000 1000 1000 1000 1000 1000 1000 1000 1000 0
1000 1000 1000 1000 1000 1000 1000 1000 1000 1000 1000 1000 1000 1000 1000 1000 1000 1000 1000 1000 1000 1000 1000 1000 1000 1000 1000 1000 1000 1000 1000 1000 1000 1000 1000 0
1000 1000 1000 1000 1000 1000 1000 1000 1000 1000 1000 1000 1000 1000 1000 1000 1000 1000 1000 1000 1000 1000 1000 1000 1000 1000 1000 1000 1000 1000 1000 1000 1000 1000 1000 0
1000 1000 1000 1000 1000 1000 1000 1000 1000 1000 1000 1000 1000 1000 1000 1000 1000 1000 1000 1000 1000 1000 1000 1000 1000 1000 1000 1000 1000 1000 1000 1000 1000 1000 1000 0
1000 1000 1000 1000 1000 1000 1000 1000 1000 1000 1000 1000 1000 1000 1000 1000 1000 1000 1000 1000 1000 1000 1000 1000 1000 1000 1000 1000 1000 1000 1000 1000 1000 1000 1000 0
1000 1000 1000 1000 1000 1000 1000 1000 1000 1000 1000 1000 1000 1000 1000 1000 1000 1000 1000 1000 1000 1000 1000 1000 1000 1000 1000 1000 1000 1000 1000 1000 1000 1000 1000 0
1000 1000 1000 1000 1000 1000 1000 1000 1000 1000 1000 1000 1000 1000 1000 1000 1000 1000 1000 1000 1000 1000 1000 1000 1000 1000 1000 1000 1000 1000 1000 1000 1000 1000 1000 0
0 0 0 0 0 0 0 0 0 0 0 0 0 0 0 0 0 0 0 0 0 0 0 0 0 0 0 0 0 0 0 0 0 0 0 0>;

	synaptics,pt05_high_b = /bits/ 16 <
266 891 1035 1034 1031 1027 1021 1021 1019 1019 1021 1012 1007 1007 1012 1015 1023 1040 907 907 908 908 908 906 907 907 906 906 908 905 904 905 904 901 784 192
709 1038 1034 1030 1028 1032 1021 1022 1021 1021 1040 1018 1013 1013 1016 1015 1015 1016 1012 1011 1012 1011 1012 1009 1012 1010 1009 1009 1010 1008 1007 1007 1008 1008 1008 781
813 1039 1033 1029 1027 1023 1020 1022 1020 1020 1021 1017 1012 1012 1014 1014 1014 1015 1013 1011 1011 1011 1012 1009 1012 1010 1009 1009 1010 1009 1007 1007 1008 1008 1009 869
813 1039 1032 1028 1026 1022 1020 1021 1020 1020 1020 1015 1011 1011 1013 1014 1012 1013 1013 1012 1012 1012 1013 1010 1013 1011 1010 1010 1011 1009 1007 1008 1009 1009 1009 866
812 1039 1032 1028 1025 1022 1020 1021 1020 1020 1020 1016 1011 1011 1013 1014 1012 1013 1014 1013 1013 1013 1014 1011 1013 1012 1011 1010 1012 1010 1007 1008 1009 1009 1009 875
813 1038 1031 1027 1025 1021 1019 1020 1019 1020 1019 1016 1011 1012 1014 1014 1012 1013 1014 1013 1012 1013 1013 1011 1013 1011 1011 1010 1011 1009 1007 1007 1009 1009 1009 881
812 1036 1032 1028 1025 1021 1020 1021 1020 1020 1019 1016 1012 1012 1013 1014 1012 1012 1014 1013 1013 1014 1013 1011 1013 1011 1011 1010 1012 1009 1008 1008 1009 1009 1010 886
755 558 1001 1029 1026 1021 1019 1020 1019 1020 1019 1016 1011 1011 1013 1013 1012 1012 1013 1012 1012 1013 1013 1011 1012 1011 1011 1010 1012 1009 1007 1007 1008 1009 1009 893
756 578 1008 1029 1025 1020 1019 1020 1019 1020 1018 1016 1010 1011 1012 1012 1011 1011 1014 1012 1017 1014 1013 1011 1012 1012 1011 1010 1013 1009 1008 1008 1009 1009 1010 902
813 1036 1031 1027 1025 1020 1018 1020 1019 1019 1018 1015 1010 1010 1012 1012 1011 1011 1013 1012 1012 1013 1014 1011 1012 1012 1010 1010 1012 1009 1008 1007 1009 1009 1009 887
813 1038 1030 1026 1025 1020 1018 1019 1020 1019 1018 1015 1010 1011 1012 1011 1011 1011 1013 1012 1013 1013 1013 1011 1012 1012 1010 1010 1011 1009 1007 1007 1009 1008 1009 878
813 1037 1029 1025 1024 1018 1017 1019 1018 1018 1017 1014 1010 1010 1011 1010 1010 1010 1013 1012 1011 1012 1012 1011 1011 1011 1009 1010 1011 1009 1006 1006 1008 1008 1009 875
812 1037 1029 1025 1024 1018 1017 1019 1018 1018 1017 1014 1009 1009 1011 1010 1010 1010 1013 1012 1012 1012 1013 1011 1011 1011 1010 1010 1011 1009 1006 1006 1008 1008 1009 869
810 1036 1028 1025 1022 1017 1016 1018 1017 1017 1016 1013 1008 1008 1010 1009 1009 1009 1013 1012 1012 1013 1013 1011 1012 1012 1010 1010 1012 1010 1008 1008 1011 1009 1011 882
695 1033 1028 1024 1021 1017 1015 1017 1016 1017 1016 1012 1007 1006 1009 1008 1009 1008 1012 1012 1032 1042 1013 1011 1011 1012 1010 1010 1012 1009 1008 1007 1010 1009 1010 778
133 790 943 944 942 940 937 938 938 938 936 936 931 930 932 932 932 932 988 983 985 997 978 981 979 978 976 975 972 973 970 971 969 957 870 281>;

	synaptics,pt05_low_b = /bits/ 16 <
100 534 620 620 618 615 612 612 610 610 612 606 604 603 606 608 613 623 544 543 544 544 544 543 543 543 543 543 544 542 541 542 541 540 470 72
425 622 620 617 616 619 612 612 612 612 623 610 607 607 609 608 608 609 606 606 606 606 606 605 606 605 605 605 605 604 603 603 604 604 604 468
487 623 619 617 615 613 611 612 611 611 612 609 606 606 608 608 607 608 607 606 606 606 606 605 606 605 605 605 605 604 603 603 604 604 604 520
487 622 618 616 615 612 611 612 611 611 611 608 606 606 607 607 606 607 607 606 607 607 607 605 607 606 605 605 606 605 604 604 604 604 605 519
487 622 618 616 614 612 611 612 611 611 611 609 606 606 607 608 607 607 607 607 607 607 607 606 607 606 606 605 606 605 604 604 605 604 605 524
487 622 618 616 614 612 611 611 611 611 610 609 606 606 607 607 607 607 607 607 607 607 607 606 607 606 606 605 606 605 604 604 605 604 605 528
486 621 618 616 614 612 611 612 611 611 611 609 606 606 607 608 607 607 607 607 607 607 607 606 607 606 606 605 606 605 604 604 605 605 605 531
452 334 600 617 615 612 611 611 611 611 610 609 606 606 607 607 606 606 607 606 606 607 607 606 606 606 606 605 606 605 604 604 604 604 605 535
453 346 604 617 614 611 610 611 611 611 610 609 605 606 607 607 606 606 607 607 609 608 607 606 606 606 606 605 607 605 604 604 605 605 605 540
487 621 618 616 614 611 610 611 611 611 610 608 605 605 606 606 606 606 607 606 606 607 607 606 607 606 605 605 606 605 604 603 605 604 605 531
487 622 617 615 614 611 610 611 611 611 610 608 605 606 606 606 606 606 607 607 607 607 607 606 606 606 605 605 606 605 604 603 604 604 605 526
487 621 616 614 613 610 609 610 610 610 609 608 605 605 606 605 605 605 607 606 606 606 607 606 606 606 605 605 606 605 603 603 604 604 605 524
486 621 616 614 613 610 610 610 610 610 609 608 605 605 606 605 605 605 607 606 606 607 607 606 606 606 605 605 606 605 603 603 604 604 605 521
485 621 616 614 613 609 609 610 609 609 609 607 604 604 605 605 605 605 607 606 607 607 607 606 606 606 605 605 606 605 604 604 606 605 606 528
416 619 616 614 612 609 608 609 609 609 609 606 603 603 604 604 604 604 607 606 619 624 607 606 606 606 605 605 606 605 604 604 605 605 605 466
50 473 565 565 564 563 561 562 562 562 561 561 558 557 559 558 558 559 592 589 590 598 586 588 587 586 585 584 582 583 581 582 581 573 521 106>;
	synaptics,pt05_gap_x_b = /bits/ 16 <
442 44 26 25 26 25 26 25 25 26 26 26 26 26 26 27 27 39 26 26 26 26 28 28 26 27 26 25 27 26 28 27 27 38 183
77 20 20 20 20 20 20 20 20 20 20 20 20 20 20 20 20 20 20 20 20 20 20 20 20 20 20 20 20 20 20 20 20 20 49
58 20 20 20 20 20 20 20 20 20 20 20 20 20 20 20 20 20 20 20 20 20 20 20 20 20 20 20 20 20 20 20 20 20 41
58 20 20 20 20 20 20 20 20 20 20 20 20 20 20 20 20 20 20 20 20 20 20 20 20 20 20 20 20 20 20 20 20 20 41
57 20 20 20 20 20 20 20 20 20 20 20 20 20 20 20 20 20 20 20 20 20 20 20 20 20 20 20 20 20 20 20 20 20 40
58 20 20 20 20 20 20 20 20 20 20 20 20 20 20 20 20 20 20 20 20 20 20 20 20 20 20 20 20 20 20 20 20 20 37
58 20 20 20 20 20 20 20 20 20 20 20 20 20 20 20 20 20 20 20 20 20 20 20 20 20 20 20 20 20 20 20 20 20 37
46 97 20 20 20 20 20 20 20 20 20 20 20 20 20 20 20 20 20 20 20 20 20 20 20 20 20 20 20 20 20 20 20 20 37
46 97 20 20 20 20 20 20 20 20 20 20 20 20 20 20 20 20 20 20 20 20 20 20 20 20 20 20 20 20 20 20 20 20 37
56 20 20 20 20 20 20 20 20 20 20 20 20 20 20 20 20 20 20 20 20 20 20 20 20 20 20 20 20 20 20 20 20 20 37
58 20 20 20 20 20 20 20 20 20 20 20 20 20 20 20 20 20 20 20 20 20 20 20 20 20 20 20 20 20 20 20 20 20 38
58 20 20 20 20 20 20 20 20 20 20 20 20 20 20 20 20 20 20 20 20 20 20 20 20 20 20 20 20 20 20 20 20 20 38
58 20 20 20 20 20 20 20 20 20 20 20 20 20 20 20 20 20 20 20 20 20 20 20 20 20 20 20 20 20 20 20 20 20 40
58 20 20 20 20 20 20 20 20 20 20 20 20 20 20 20 20 20 20 20 20 20 20 20 20 20 20 20 20 20 20 20 20 20 38
80 20 20 20 20 20 20 20 20 20 20 20 20 20 20 20 20 20 20 20 20 20 20 20 20 20 20 20 20 20 20 20 20 20 49
993 47 26 26 27 26 26 26 25 26 26 26 26 26 26 26 26 32 27 26 25 26 26 25 25 26 26 26 26 26 25 26 26 35 176>;
	synaptics,pt05_gap_y_b = /bits/ 16 <
351 44 22 27 27 27 26 27 26 27 27 27 27 27 25 27 27 27 36 35 36 36 36 34 36 35 35 35 35 36 36 35 35 36 57 557
40 20 20 20 20 20 20 20 20 20 20 20 20 20 20 20 20 20 20 20 20 20 20 20 20 20 20 20 20 20 20 20 20 20 20 38
26 20 20 20 20 20 20 20 20 20 20 20 20 20 20 20 20 20 20 20 20 20 20 20 20 20 20 20 20 20 20 20 20 20 20 25
21 20 20 20 20 20 20 20 20 20 20 20 20 20 20 20 20 20 20 20 20 20 20 20 20 20 20 20 20 20 20 20 20 20 20 28
23 20 20 20 20 20 20 20 20 20 20 20 20 20 20 20 20 20 20 20 20 20 20 20 20 20 20 20 20 20 20 20 20 20 20 28
28 20 20 20 20 20 20 20 20 20 20 20 20 20 20 20 20 20 20 20 20 20 20 20 20 20 20 20 20 20 20 20 20 20 20 28
29 65 20 20 20 20 20 20 20 20 20 20 20 20 20 20 20 20 20 20 20 20 20 20 20 20 20 20 20 20 20 20 20 20 20 28
22 20 20 20 20 20 20 20 20 20 20 20 20 20 20 20 20 20 20 20 20 20 20 20 20 20 20 20 20 20 20 20 20 20 20 28
30 101 20 20 20 20 20 20 20 20 20 20 20 20 20 20 20 20 20 20 20 20 20 20 20 20 20 20 20 20 20 20 20 20 20 28
26 20 20 20 20 20 20 20 20 20 20 20 20 20 20 20 20 20 20 20 20 20 20 20 20 20 20 20 20 20 20 20 20 20 20 28
29 20 20 20 20 20 20 20 20 20 20 20 20 20 20 20 20 20 20 20 20 20 20 20 20 20 20 20 20 20 20 20 20 20 20 25
22 20 20 20 20 20 20 20 20 20 20 20 20 20 20 20 20 20 20 20 20 20 20 20 20 20 20 20 20 20 20 20 20 20 20 28
25 20 20 20 20 20 20 20 20 20 20 20 20 20 20 20 20 20 20 20 20 20 20 20 20 20 20 20 20 20 20 20 20 20 20 28
37 20 20 20 20 20 20 20 20 20 20 20 20 20 20 20 20 20 20 20 20 20 20 20 20 20 20 20 20 20 20 20 20 20 20 36
189 47 33 33 33 33 33 33 33 33 33 33 33 33 33 33 33 33 27 27 27 27 27 27 27 27 27 27 27 27 27 27 27 33 40 173>;

	synaptics,pt0a_high_b = /bits/ 16 <
16 16 16 16 16 16 16 16 16 16 16 16 16 16 16 16 16 16 16 16 16 16 16 16 16 16 16 16 16 16 16 16 16 16 16 16
16 16 16 16 16 16 16 16 16 16 16 16 16 16 16 16 16 16 16 16 16 16 16 16 16 16 16 16 16 16 16 16 16 16 16 16
16 16 16 16 16 16 16 16 16 16 16 16 16 16 16 16 16 16 16 16 16 16 16 16 16 16 16 16 16 16 16 16 16 16 16 16
16 16 16 16 16 16 16 16 16 16 16 16 16 16 16 16 16 16 16 16 16 16 16 16 16 16 16 16 16 16 16 16 16 16 16 16
16 16 16 16 16 16 16 16 16 16 16 16 16 16 16 16 16 16 16 16 16 16 16 16 16 16 16 16 16 16 16 16 16 16 16 16
16 16 16 16 16 16 16 16 16 16 16 16 16 16 16 16 16 16 16 16 16 16 16 16 16 16 16 16 16 16 16 16 16 16 16 16
16 16 16 16 16 16 16 16 16 16 16 16 16 16 16 16 16 16 16 16 16 16 16 16 16 16 16 16 16 16 16 16 16 16 16 16
16 16 16 16 16 16 16 16 16 16 16 16 16 16 16 16 16 16 16 16 16 16 16 16 16 16 16 16 16 16 16 16 16 16 16 16
16 16 16 16 16 16 16 16 16 16 16 16 16 16 16 16 16 16 16 16 16 16 16 16 16 16 16 16 16 16 16 16 16 16 16 16
16 16 16 16 16 16 16 16 16 16 16 16 16 16 16 16 16 16 16 16 16 16 16 16 16 16 16 16 16 16 16 16 16 16 16 16
16 16 16 16 16 16 16 16 16 16 16 16 16 16 16 16 16 16 16 16 16 16 16 16 16 16 16 16 16 16 16 16 16 16 16 16
16 16 16 16 16 16 16 16 16 16 16 16 16 16 16 16 16 16 16 16 16 16 16 16 16 16 16 16 16 16 16 16 16 16 16 16
16 16 16 16 16 16 16 16 16 16 16 16 16 16 16 16 16 16 16 16 16 16 16 16 16 16 16 16 16 16 16 16 16 16 16 16
16 16 16 16 16 16 16 16 16 16 16 16 16 16 16 16 16 16 16 16 16 16 16 16 16 16 16 16 16 16 16 16 16 16 16 16
16 16 16 16 16 16 16 16 16 16 16 16 16 16 16 16 16 16 16 16 16 16 16 16 16 16 16 16 16 16 16 16 16 16 16 16
16 16 16 16 16 16 16 16 16 16 16 16 16 16 16 16 16 16 16 16 16 16 16 16 16 16 16 16 16 16 16 16 16 16 16 16>;
	synaptics,pt0a_low_b = /bits/ 16 <
(-16) (-16) (-16) (-16) (-16) (-16) (-16) (-16) (-16) (-16) (-16) (-16) (-16) (-16) (-16) (-16) (-16) (-16) (-16) (-16) (-16) (-16) (-16) (-16) (-16) (-16) (-16) (-16) (-16) (-16) (-16) (-16) (-16) (-16) (-16) (-16)
(-16) (-16) (-16) (-16) (-16) (-16) (-16) (-16) (-16) (-16) (-16) (-16) (-16) (-16) (-16) (-16) (-16) (-16) (-16) (-16) (-16) (-16) (-16) (-16) (-16) (-16) (-16) (-16) (-16) (-16) (-16) (-16) (-16) (-16) (-16) (-16)
(-16) (-16) (-16) (-16) (-16) (-16) (-16) (-16) (-16) (-16) (-16) (-16) (-16) (-16) (-16) (-16) (-16) (-16) (-16) (-16) (-16) (-16) (-16) (-16) (-16) (-16) (-16) (-16) (-16) (-16) (-16) (-16) (-16) (-16) (-16) (-16)
(-16) (-16) (-16) (-16) (-16) (-16) (-16) (-16) (-16) (-16) (-16) (-16) (-16) (-16) (-16) (-16) (-16) (-16) (-16) (-16) (-16) (-16) (-16) (-16) (-16) (-16) (-16) (-16) (-16) (-16) (-16) (-16) (-16) (-16) (-16) (-16)
(-16) (-16) (-16) (-16) (-16) (-16) (-16) (-16) (-16) (-16) (-16) (-16) (-16) (-16) (-16) (-16) (-16) (-16) (-16) (-16) (-16) (-16) (-16) (-16) (-16) (-16) (-16) (-16) (-16) (-16) (-16) (-16) (-16) (-16) (-16) (-16)
(-16) (-16) (-16) (-16) (-16) (-16) (-16) (-16) (-16) (-16) (-16) (-16) (-16) (-16) (-16) (-16) (-16) (-16) (-16) (-16) (-16) (-16) (-16) (-16) (-16) (-16) (-16) (-16) (-16) (-16) (-16) (-16) (-16) (-16) (-16) (-16)
(-16) (-16) (-16) (-16) (-16) (-16) (-16) (-16) (-16) (-16) (-16) (-16) (-16) (-16) (-16) (-16) (-16) (-16) (-16) (-16) (-16) (-16) (-16) (-16) (-16) (-16) (-16) (-16) (-16) (-16) (-16) (-16) (-16) (-16) (-16) (-16)
(-16) (-16) (-16) (-16) (-16) (-16) (-16) (-16) (-16) (-16) (-16) (-16) (-16) (-16) (-16) (-16) (-16) (-16) (-16) (-16) (-16) (-16) (-16) (-16) (-16) (-16) (-16) (-16) (-16) (-16) (-16) (-16) (-16) (-16) (-16) (-16)
(-16) (-16) (-16) (-16) (-16) (-16) (-16) (-16) (-16) (-16) (-16) (-16) (-16) (-16) (-16) (-16) (-16) (-16) (-16) (-16) (-16) (-16) (-16) (-16) (-16) (-16) (-16) (-16) (-16) (-16) (-16) (-16) (-16) (-16) (-16) (-16)
(-16) (-16) (-16) (-16) (-16) (-16) (-16) (-16) (-16) (-16) (-16) (-16) (-16) (-16) (-16) (-16) (-16) (-16) (-16) (-16) (-16) (-16) (-16) (-16) (-16) (-16) (-16) (-16) (-16) (-16) (-16) (-16) (-16) (-16) (-16) (-16)
(-16) (-16) (-16) (-16) (-16) (-16) (-16) (-16) (-16) (-16) (-16) (-16) (-16) (-16) (-16) (-16) (-16) (-16) (-16) (-16) (-16) (-16) (-16) (-16) (-16) (-16) (-16) (-16) (-16) (-16) (-16) (-16) (-16) (-16) (-16) (-16)
(-16) (-16) (-16) (-16) (-16) (-16) (-16) (-16) (-16) (-16) (-16) (-16) (-16) (-16) (-16) (-16) (-16) (-16) (-16) (-16) (-16) (-16) (-16) (-16) (-16) (-16) (-16) (-16) (-16) (-16) (-16) (-16) (-16) (-16) (-16) (-16)
(-16) (-16) (-16) (-16) (-16) (-16) (-16) (-16) (-16) (-16) (-16) (-16) (-16) (-16) (-16) (-16) (-16) (-16) (-16) (-16) (-16) (-16) (-16) (-16) (-16) (-16) (-16) (-16) (-16) (-16) (-16) (-16) (-16) (-16) (-16) (-16)
(-16) (-16) (-16) (-16) (-16) (-16) (-16) (-16) (-16) (-16) (-16) (-16) (-16) (-16) (-16) (-16) (-16) (-16) (-16) (-16) (-16) (-16) (-16) (-16) (-16) (-16) (-16) (-16) (-16) (-16) (-16) (-16) (-16) (-16) (-16) (-16)
(-16) (-16) (-16) (-16) (-16) (-16) (-16) (-16) (-16) (-16) (-16) (-16) (-16) (-16) (-16) (-16) (-16) (-16) (-16) (-16) (-16) (-16) (-16) (-16) (-16) (-16) (-16) (-16) (-16) (-16) (-16) (-16) (-16) (-16) (-16) (-16)
(-16) (-16) (-16) (-16) (-16) (-16) (-16) (-16) (-16) (-16) (-16) (-16) (-16) (-16) (-16) (-16) (-16) (-16) (-16) (-16) (-16) (-16) (-16) (-16) (-16) (-16) (-16) (-16) (-16) (-16) (-16) (-16) (-16) (-16) (-16) (-16)>;

	synaptics,pt10_high_b = /bits/ 16 <
100 100 100 100 100 100 100 100 100 100 100 100 100 100 100 100 100 100 100 100 100 100 100 100 100 100 100 100 100 100 100 100 100 100 100 100
100 100 100 100 100 100 100 100 100 100 100 100 100 100 100 100 100 100 100 100 100 100 100 100 100 100 100 100 100 100 100 100 100 100 100 100
100 100 100 100 100 100 100 100 100 100 100 100 100 100 100 100 100 100 100 100 100 100 100 100 100 100 100 100 100 100 100 100 100 100 100 100
100 100 100 100 100 100 100 100 100 100 100 100 100 100 100 100 100 100 100 100 100 100 100 100 100 100 100 100 100 100 100 100 100 100 100 100
100 100 100 100 100 100 100 100 100 100 100 100 100 100 100 100 100 100 100 100 100 100 100 100 100 100 100 100 100 100 100 100 100 100 100 100
100 100 100 100 100 100 100 100 100 100 100 100 100 100 100 100 100 100 100 100 100 100 100 100 100 100 100 100 100 100 100 100 100 100 100 100
100 100 100 100 100 100 100 100 100 100 100 100 100 100 100 100 100 100 100 100 100 100 100 100 100 100 100 100 100 100 100 100 100 100 100 100
100 100 100 100 100 100 100 100 100 100 100 100 100 100 100 100 100 100 100 100 100 100 100 100 100 100 100 100 100 100 100 100 100 100 100 100
100 100 100 100 100 100 100 100 100 100 100 100 100 100 100 100 100 100 100 100 100 100 100 100 100 100 100 100 100 100 100 100 100 100 100 100
100 100 100 100 100 100 100 100 100 100 100 100 100 100 100 100 100 100 100 100 100 100 100 100 100 100 100 100 100 100 100 100 100 100 100 100
100 100 100 100 100 100 100 100 100 100 100 100 100 100 100 100 100 100 100 100 100 100 100 100 100 100 100 100 100 100 100 100 100 100 100 100
100 100 100 100 100 100 100 100 100 100 100 100 100 100 100 100 100 100 100 100 100 100 100 100 100 100 100 100 100 100 100 100 100 100 100 100
100 100 100 100 100 100 100 100 100 100 100 100 100 100 100 100 100 100 100 100 100 100 100 100 100 100 100 100 100 100 100 100 100 100 100 100
100 100 100 100 100 100 100 100 100 100 100 100 100 100 100 100 100 100 100 100 100 100 100 100 100 100 100 100 100 100 100 100 100 100 100 100
100 100 100 100 100 100 100 100 100 100 100 100 100 100 100 100 100 100 100 100 100 100 100 100 100 100 100 100 100 100 100 100 100 100 100 100
100 100 100 100 100 100 100 100 100 100 100 100 100 100 100 100 100 100 100 100 100 100 100 100 100 100 100 100 100 100 100 100 100 100 100 100>;
	synaptics,pt10_low_b = /bits/ 16 <
0 0 0 0 0 0 0 0 0 0 0 0 0 0 0 0 0 0 0 0 0 0 0 0 0 0 0 0 0 0 0 0 0 0 0 0
0 0 0 0 0 0 0 0 0 0 0 0 0 0 0 0 0 0 0 0 0 0 0 0 0 0 0 0 0 0 0 0 0 0 0 0
0 0 0 0 0 0 0 0 0 0 0 0 0 0 0 0 0 0 0 0 0 0 0 0 0 0 0 0 0 0 0 0 0 0 0 0
0 0 0 0 0 0 0 0 0 0 0 0 0 0 0 0 0 0 0 0 0 0 0 0 0 0 0 0 0 0 0 0 0 0 0 0
0 0 0 0 0 0 0 0 0 0 0 0 0 0 0 0 0 0 0 0 0 0 0 0 0 0 0 0 0 0 0 0 0 0 0 0
0 0 0 0 0 0 0 0 0 0 0 0 0 0 0 0 0 0 0 0 0 0 0 0 0 0 0 0 0 0 0 0 0 0 0 0
0 0 0 0 0 0 0 0 0 0 0 0 0 0 0 0 0 0 0 0 0 0 0 0 0 0 0 0 0 0 0 0 0 0 0 0
0 0 0 0 0 0 0 0 0 0 0 0 0 0 0 0 0 0 0 0 0 0 0 0 0 0 0 0 0 0 0 0 0 0 0 0
0 0 0 0 0 0 0 0 0 0 0 0 0 0 0 0 0 0 0 0 0 0 0 0 0 0 0 0 0 0 0 0 0 0 0 0
0 0 0 0 0 0 0 0 0 0 0 0 0 0 0 0 0 0 0 0 0 0 0 0 0 0 0 0 0 0 0 0 0 0 0 0
0 0 0 0 0 0 0 0 0 0 0 0 0 0 0 0 0 0 0 0 0 0 0 0 0 0 0 0 0 0 0 0 0 0 0 0
0 0 0 0 0 0 0 0 0 0 0 0 0 0 0 0 0 0 0 0 0 0 0 0 0 0 0 0 0 0 0 0 0 0 0 0
0 0 0 0 0 0 0 0 0 0 0 0 0 0 0 0 0 0 0 0 0 0 0 0 0 0 0 0 0 0 0 0 0 0 0 0
0 0 0 0 0 0 0 0 0 0 0 0 0 0 0 0 0 0 0 0 0 0 0 0 0 0 0 0 0 0 0 0 0 0 0 0
0 0 0 0 0 0 0 0 0 0 0 0 0 0 0 0 0 0 0 0 0 0 0 0 0 0 0 0 0 0 0 0 0 0 0 0
0 0 0 0 0 0 0 0 0 0 0 0 0 0 0 0 0 0 0 0 0 0 0 0 0 0 0 0 0 0 0 0 0 0 0 0>;
	synaptics,pt10_gap_x_b = /bits/ 16 <
30 30 30 30 30 30 30 30 30 30 30 30 30 30 30 30 30 30 30 30 30 30 30 30 30 30 30 30 30 30 30 30 30 30 30
30 30 30 30 30 30 30 30 30 30 30 30 30 30 30 30 30 30 30 30 30 30 30 30 30 30 30 30 30 30 30 30 30 30 30
30 30 30 30 30 30 30 30 30 30 30 30 30 30 30 30 30 30 30 30 30 30 30 30 30 30 30 30 30 30 30 30 30 30 30
30 30 30 30 30 30 30 30 30 30 30 30 30 30 30 30 30 30 30 30 30 30 30 30 30 30 30 30 30 30 30 30 30 30 30
30 30 30 30 30 30 30 30 30 30 30 30 30 30 30 30 30 30 30 30 30 30 30 30 30 30 30 30 30 30 30 30 30 30 30
30 30 30 30 30 30 30 30 30 30 30 30 30 30 30 30 30 30 30 30 30 30 30 30 30 30 30 30 30 30 30 30 30 30 30
30 30 30 30 30 30 30 30 30 30 30 30 30 30 30 30 30 30 30 30 30 30 30 30 30 30 30 30 30 30 30 30 30 30 30
30 30 30 30 30 30 30 30 30 30 30 30 30 30 30 30 30 30 30 30 30 30 30 30 30 30 30 30 30 30 30 30 30 30 30
30 30 30 30 30 30 30 30 30 30 30 30 30 30 30 30 30 30 30 30 30 30 30 30 30 30 30 30 30 30 30 30 30 30 30
30 30 30 30 30 30 30 30 30 30 30 30 30 30 30 30 30 30 30 30 30 30 30 30 30 30 30 30 30 30 30 30 30 30 30
30 30 30 30 30 30 30 30 30 30 30 30 30 30 30 30 30 30 30 30 30 30 30 30 30 30 30 30 30 30 30 30 30 30 30
30 30 30 30 30 30 30 30 30 30 30 30 30 30 30 30 30 30 30 30 30 30 30 30 30 30 30 30 30 30 30 30 30 30 30
30 30 30 30 30 30 30 30 30 30 30 30 30 30 30 30 30 30 30 30 30 30 30 30 30 30 30 30 30 30 30 30 30 30 30
30 30 30 30 30 30 30 30 30 30 30 30 30 30 30 30 30 30 30 30 30 30 30 30 30 30 30 30 30 30 30 30 30 30 30
30 30 30 30 30 30 30 30 30 30 30 30 30 30 30 30 30 30 30 30 30 30 30 30 30 30 30 30 30 30 30 30 30 30 30
30 30 30 30 30 30 30 30 30 30 30 30 30 30 30 30 30 30 30 30 30 30 30 30 30 30 30 30 30 30 30 30 30 30 30>;
	synaptics,pt10_gap_y_b = /bits/ 16 <
30 30 30 30 30 30 30 30 30 30 30 30 30 30 30 30 30 30 30 30 30 30 30 30 30 30 30 30 30 30 30 30 30 30 30 30
30 30 30 30 30 30 30 30 30 30 30 30 30 30 30 30 30 30 30 30 30 30 30 30 30 30 30 30 30 30 30 30 30 30 30 30
30 30 30 30 30 30 30 30 30 30 30 30 30 30 30 30 30 30 30 30 30 30 30 30 30 30 30 30 30 30 30 30 30 30 30 30
30 30 30 30 30 30 30 30 30 30 30 30 30 30 30 30 30 30 30 30 30 30 30 30 30 30 30 30 30 30 30 30 30 30 30 30
30 30 30 30 30 30 30 30 30 30 30 30 30 30 30 30 30 30 30 30 30 30 30 30 30 30 30 30 30 30 30 30 30 30 30 30
30 30 30 30 30 30 30 30 30 30 30 30 30 30 30 30 30 30 30 30 30 30 30 30 30 30 30 30 30 30 30 30 30 30 30 30
30 30 30 30 30 30 30 30 30 30 30 30 30 30 30 30 30 30 30 30 30 30 30 30 30 30 30 30 30 30 30 30 30 30 30 30
30 30 30 30 30 30 30 30 30 30 30 30 30 30 30 30 30 30 30 30 30 30 30 30 30 30 30 30 30 30 30 30 30 30 30 30
30 30 30 30 30 30 30 30 30 30 30 30 30 30 30 30 30 30 30 30 30 30 30 30 30 30 30 30 30 30 30 30 30 30 30 30
30 30 30 30 30 30 30 30 30 30 30 30 30 30 30 30 30 30 30 30 30 30 30 30 30 30 30 30 30 30 30 30 30 30 30 30
30 30 30 30 30 30 30 30 30 30 30 30 30 30 30 30 30 30 30 30 30 30 30 30 30 30 30 30 30 30 30 30 30 30 30 30
30 30 30 30 30 30 30 30 30 30 30 30 30 30 30 30 30 30 30 30 30 30 30 30 30 30 30 30 30 30 30 30 30 30 30 30
30 30 30 30 30 30 30 30 30 30 30 30 30 30 30 30 30 30 30 30 30 30 30 30 30 30 30 30 30 30 30 30 30 30 30 30
30 30 30 30 30 30 30 30 30 30 30 30 30 30 30 30 30 30 30 30 30 30 30 30 30 30 30 30 30 30 30 30 30 30 30 30
30 30 30 30 30 30 30 30 30 30 30 30 30 30 30 30 30 30 30 30 30 30 30 30 30 30 30 30 30 30 30 30 30 30 30 30>;

	synaptics,pt11_high_b = /bits/ 16 <
200 200 200 200 200 200 200 200 200 200 200 200 200 200 200 200 200 200 200 200 200 200 200 200 200 200 200 200 200 200 200 200 200 200 200 200
200 200 200 200 200 200 200 200 200 200 200 200 200 200 200 200 200 200 200 200 200 200 200 200 200 200 200 200 200 200 200 200 200 200 200 200
200 200 200 200 200 200 200 200 200 200 200 200 200 200 200 200 200 200 200 200 200 200 200 200 200 200 200 200 200 200 200 200 200 200 200 200
200 200 200 200 200 200 200 200 200 200 200 200 200 200 200 200 200 200 200 200 200 200 200 200 200 200 200 200 200 200 200 200 200 200 200 200
200 200 200 200 200 200 200 200 200 200 200 200 200 200 200 200 200 200 200 200 200 200 200 200 200 200 200 200 200 200 200 200 200 200 200 200
200 200 200 200 200 200 200 200 200 200 200 200 200 200 200 200 200 200 200 200 200 200 200 200 200 200 200 200 200 200 200 200 200 200 200 200
200 200 200 200 200 200 200 200 200 200 200 200 200 200 200 200 200 200 200 200 200 200 200 200 200 200 200 200 200 200 200 200 200 200 200 200
200 200 200 200 200 200 200 200 200 200 200 200 200 200 200 200 200 200 200 200 200 200 200 200 200 200 200 200 200 200 200 200 200 200 200 200
200 200 200 200 200 200 200 200 200 200 200 200 200 200 200 200 200 200 200 200 200 200 200 200 200 200 200 200 200 200 200 200 200 200 200 200
200 200 200 200 200 200 200 200 200 200 200 200 200 200 200 200 200 200 200 200 200 200 200 200 200 200 200 200 200 200 200 200 200 200 200 200
200 200 200 200 200 200 200 200 200 200 200 200 200 200 200 200 200 200 200 200 200 200 200 200 200 200 200 200 200 200 200 200 200 200 200 200
200 200 200 200 200 200 200 200 200 200 200 200 200 200 200 200 200 200 200 200 200 200 200 200 200 200 200 200 200 200 200 200 200 200 200 200
200 200 200 200 200 200 200 200 200 200 200 200 200 200 200 200 200 200 200 200 200 200 200 200 200 200 200 200 200 200 200 200 200 200 200 200
200 200 200 200 200 200 200 200 200 200 200 200 200 200 200 200 200 200 200 200 200 200 200 200 200 200 200 200 200 200 200 200 200 200 200 200
200 200 200 200 200 200 200 200 200 200 200 200 200 200 200 200 200 200 200 200 200 200 200 200 200 200 200 200 200 200 200 200 200 200 200 200
200 200 200 200 200 200 200 200 200 200 200 200 200 200 200 200 200 200 200 200 200 200 200 200 200 200 200 200 200 200 200 200 200 200 200 200>;
	synaptics,pt11_low_b = /bits/ 16 <
70 70 70 70 70 70 70 70 70 70 70 70 70 70 70 70 70 70 70 70 70 70 70 70 70 70 70 70 70 70 70 70 70 70 70 70
70 70 70 70 70 70 70 70 70 70 70 70 70 70 70 70 70 70 70 70 70 70 70 70 70 70 70 70 70 70 70 70 70 70 70 70
70 70 70 70 70 70 70 70 70 70 70 70 70 70 70 70 70 70 70 70 70 70 70 70 70 70 70 70 70 70 70 70 70 70 70 70
70 70 70 70 70 70 70 70 70 70 70 70 70 70 70 70 70 70 70 70 70 70 70 70 70 70 70 70 70 70 70 70 70 70 70 70
70 70 70 70 70 70 70 70 70 70 70 70 70 70 70 70 70 70 70 70 70 70 70 70 70 70 70 70 70 70 70 70 70 70 70 70
70 70 70 70 70 70 70 70 70 70 70 70 70 70 70 70 70 70 70 70 70 70 70 70 70 70 70 70 70 70 70 70 70 70 70 70
70 70 70 70 70 70 70 70 70 70 70 70 70 70 70 70 70 70 70 70 70 70 70 70 70 70 70 70 70 70 70 70 70 70 70 70
70 70 70 70 70 70 70 70 70 70 70 70 70 70 70 70 70 70 70 70 70 70 70 70 70 70 70 70 70 70 70 70 70 70 70 70
70 70 70 70 70 70 70 70 70 70 70 70 70 70 70 70 70 70 70 70 70 70 70 70 70 70 70 70 70 70 70 70 70 70 70 70
70 70 70 70 70 70 70 70 70 70 70 70 70 70 70 70 70 70 70 70 70 70 70 70 70 70 70 70 70 70 70 70 70 70 70 70
70 70 70 70 70 70 70 70 70 70 70 70 70 70 70 70 70 70 70 70 70 70 70 70 70 70 70 70 70 70 70 70 70 70 70 70
70 70 70 70 70 70 70 70 70 70 70 70 70 70 70 70 70 70 70 70 70 70 70 70 70 70 70 70 70 70 70 70 70 70 70 70
70 70 70 70 70 70 70 70 70 70 70 70 70 70 70 70 70 70 70 70 70 70 70 70 70 70 70 70 70 70 70 70 70 70 70 70
70 70 70 70 70 70 70 70 70 70 70 70 70 70 70 70 70 70 70 70 70 70 70 70 70 70 70 70 70 70 70 70 70 70 70 70
70 70 70 70 70 70 70 70 70 70 70 70 70 70 70 70 70 70 70 70 70 70 70 70 70 70 70 70 70 70 70 70 70 70 70 70
70 70 70 70 70 70 70 70 70 70 70 70 70 70 70 70 70 70 70 70 70 70 70 70 70 70 70 70 70 70 70 70 70 70 70 70>;

	synaptics,pt12_high_b = <
230776 241858 243876 242669 242666 241878 241951 241305 241042 241127 240345 240579 241145 240901 240307 240080 240063 239794 232474 232365 231990 231607 231175 231536 230453 230080 231064 230758 230736 230967 231340 230604 230224 230061 228100 209701 514393 525768 526473 526385 525617 526135 526358 528056 521820 520609 519946 520087 520863 521260 519848 509155>;
	synaptics,pt12_low_b = <
138465 145114 146325 145601 145599 145126 145170 144782 144624 144675 144206 144347 144686 144540 144183 144047 144037 143875 139483 139418 139193 138963 138704 138921 138271 138047 138637 138454 138441 138579 138803 138362 138133 138036 136859 125820 308635 315460 315883 315830 315370 315680 315814 316833 313091 312364 311967 312051 312517 312755 311908 305492>;

	synaptics,pt16_high_b = /bits/ 16 <
286 902 1044 1045 1042 1038 1032 1032 1030 1030 1033 1023 1018 1018 1022 1026 1034 1051 919 918 918 920 919 917 918 918 917 917 918 915 914 915 915 912 795 210
722 1045 1040 1037 1035 1039 1028 1029 1028 1029 1050 1025 1020 1021 1022 1022 1022 1024 1019 1017 1018 1020 1019 1017 1017 1017 1016 1016 1017 1014 1013 1014 1014 1014 1013 792
823 1044 1036 1034 1032 1027 1025 1026 1025 1026 1027 1023 1017 1017 1018 1019 1018 1020 1017 1015 1015 1018 1016 1014 1015 1015 1014 1014 1015 1012 1010 1012 1012 1012 1012 877
827 1049 1041 1039 1037 1032 1029 1031 1031 1031 1031 1027 1021 1021 1023 1023 1023 1023 1023 1021 1022 1024 1023 1021 1021 1021 1021 1021 1021 1018 1017 1018 1018 1018 1018 878
827 1049 1041 1039 1037 1032 1030 1032 1031 1031 1032 1028 1022 1022 1023 1025 1023 1024 1024 1022 1023 1025 1024 1022 1022 1022 1021 1021 1022 1019 1017 1019 1019 1019 1019 887
825 1046 1039 1037 1034 1030 1027 1029 1028 1029 1029 1025 1020 1019 1022 1021 1021 1021 1021 1020 1020 1023 1021 1019 1020 1020 1019 1019 1019 1016 1015 1016 1016 1016 1016 892
826 1046 1042 1040 1037 1032 1030 1032 1030 1031 1032 1028 1023 1022 1023 1024 1023 1024 1024 1022 1023 1025 1024 1022 1022 1022 1021 1021 1021 1019 1017 1018 1018 1019 1019 900
771 569 1010 1040 1037 1032 1030 1031 1030 1031 1031 1027 1022 1021 1023 1023 1022 1023 1024 1022 1022 1025 1024 1021 1022 1021 1021 1021 1021 1018 1017 1018 1018 1018 1019 907
771 591 1019 1041 1037 1032 1030 1031 1030 1031 1031 1027 1022 1021 1023 1023 1022 1023 1024 1023 1027 1026 1024 1022 1022 1022 1021 1021 1022 1019 1017 1019 1019 1019 1019 916
828 1049 1044 1042 1039 1034 1032 1034 1032 1033 1033 1029 1024 1024 1025 1026 1025 1025 1027 1025 1025 1028 1027 1024 1025 1025 1024 1024 1024 1022 1021 1021 1021 1021 1021 903
830 1052 1044 1042 1040 1035 1033 1034 1033 1034 1034 1030 1025 1024 1026 1027 1026 1026 1028 1026 1027 1029 1028 1025 1026 1026 1025 1025 1025 1022 1021 1022 1022 1022 1022 895
828 1050 1043 1041 1039 1034 1032 1033 1032 1033 1033 1029 1024 1023 1025 1026 1025 1025 1027 1025 1026 1028 1027 1024 1025 1025 1024 1024 1024 1022 1020 1021 1021 1021 1021 891
825 1046 1039 1036 1034 1030 1027 1029 1028 1028 1029 1025 1020 1019 1021 1022 1021 1021 1023 1022 1022 1024 1023 1021 1021 1021 1020 1020 1020 1018 1016 1018 1018 1018 1017 881
822 1043 1035 1033 1031 1026 1024 1026 1024 1025 1025 1021 1016 1016 1018 1018 1017 1018 1021 1019 1020 1023 1021 1019 1019 1019 1018 1018 1019 1016 1015 1017 1018 1017 1017 894
710 1044 1039 1036 1033 1029 1027 1028 1027 1028 1028 1024 1019 1018 1020 1021 1020 1020 1024 1023 1043 1054 1024 1022 1022 1023 1021 1022 1022 1020 1018 1020 1020 1021 1020 792
153 803 955 956 955 951 949 951 950 951 951 947 942 942 943 944 943 944 999 995 997 1012 990 992 991 990 987 985 984 985 982 982 980 970 881 299>;

	synaptics,pt16_low_b = /bits/ 16 <
108 540 626 626 624 622 618 618 617 617 619 613 610 610 612 615 620 630 550 550 550 551 551 549 550 550 549 549 550 548 547 548 548 547 476 79
432 626 623 622 620 622 616 617 616 616 629 614 611 612 612 613 612 613 611 610 610 611 611 609 610 609 609 609 609 608 607 608 608 608 607 475
493 625 621 620 618 616 614 615 614 615 615 613 609 609 610 611 610 611 609 608 608 610 609 608 608 608 608 608 608 606 605 606 606 606 606 525
495 629 624 623 621 618 617 618 618 618 618 615 612 612 613 613 613 613 613 612 612 614 613 612 612 612 612 612 612 610 609 610 610 610 610 526
495 629 624 623 621 619 617 618 618 618 618 616 612 612 613 614 613 614 613 613 613 614 614 612 613 612 612 612 612 611 610 611 611 611 611 532
494 627 623 621 620 617 616 617 616 616 617 614 611 611 612 612 612 612 612 611 611 613 612 611 611 611 610 610 611 609 608 609 609 609 609 534
495 627 624 623 621 619 617 618 617 618 618 616 613 612 613 614 613 613 614 613 613 614 614 612 613 612 612 612 612 610 609 610 610 610 610 539
462 341 605 623 621 618 617 618 617 618 618 615 612 612 613 613 613 613 613 612 613 614 613 612 612 612 612 612 612 610 609 610 610 610 610 544
462 354 610 624 621 618 617 618 617 618 618 615 612 612 613 613 613 613 614 613 616 615 614 612 613 613 612 612 613 611 610 611 611 611 611 549
496 629 626 624 623 620 618 619 619 619 619 617 614 613 614 615 614 614 615 614 614 616 615 614 614 614 614 614 614 612 612 612 612 612 612 541
497 630 626 624 623 620 619 620 619 619 620 617 614 614 615 615 615 615 616 615 615 617 616 614 615 615 614 614 614 613 612 613 613 612 612 536
496 629 625 624 622 620 618 619 618 619 619 617 613 613 614 615 614 614 615 614 615 616 615 614 614 614 614 613 614 612 611 612 612 612 612 534
494 627 622 621 620 617 616 617 616 616 617 614 611 611 612 612 612 612 613 612 612 614 613 612 612 612 611 611 611 610 609 610 610 610 610 528
492 625 620 619 618 615 614 615 614 614 614 612 609 609 610 610 609 610 612 611 611 613 612 610 611 611 610 610 611 609 608 609 610 609 609 535
425 626 622 621 619 616 615 616 615 616 616 614 610 610 611 612 611 611 614 613 625 632 614 612 613 613 612 612 612 611 610 611 611 612 611 475
57 481 572 573 572 570 569 570 569 570 570 568 565 564 565 566 565 566 599 596 597 607 593 594 594 593 591 590 590 590 588 588 587 581 528 113>;

	synaptics,pt_tag_moisture_b = /bits/ 16 <
800 800 800 800 800 800 800 800 800 800 800 800 800 800 800 800 800 800 800 800 800 800 800 800 800 800 800 800 800 800 800 800 800 800 800 0
800 800 800 800 800 800 800 800 800 800 800 800 800 800 800 800 800 800 800 800 800 800 800 800 800 800 800 800 800 800 800 800 800 800 800 0
800 800 80 80 80 80 80 80 80 80 80 80 80 80 80 80 80 80 80 80 80 80 80 80 80 80 80 80 80 80 80 80 80 800 800 0
800 800 80 80 80 80 80 80 80 80 80 80 80 80 80 80 80 80 80 80 80 80 80 80 80 80 80 80 80 80 80 80 80 800 800 0
800 800 80 80 80 80 80 80 80 80 80 80 80 80 80 80 80 80 80 80 80 80 80 80 80 80 80 80 80 80 80 80 80 800 800 0
800 800 80 80 80 80 80 80 80 80 80 80 80 80 80 80 80 80 80 80 80 80 80 80 80 80 80 80 80 80 80 80 80 800 800 0
800 800 800 80 80 80 80 80 80 80 80 80 80 80 80 80 80 80 80 80 80 80 80 80 80 80 80 80 80 80 80 80 80 800 800 0
800 800 80 80 80 80 80 80 80 80 80 80 80 80 80 80 80 80 80 80 80 80 80 80 80 80 80 80 80 80 80 80 80 800 800 0
800 800 800 80 80 80 80 80 80 80 80 80 80 80 80 80 80 80 80 80 80 80 80 80 80 80 80 80 80 80 80 80 80 800 800 0
800 800 80 80 80 80 80 80 80 80 80 80 80 80 80 80 80 80 80 80 80 80 80 80 80 80 80 80 80 80 80 80 80 800 800 0
800 800 80 80 80 80 80 80 80 80 80 80 80 80 80 80 80 80 80 80 80 80 80 80 80 80 80 80 80 80 80 80 80 800 800 0
800 800 80 80 80 80 80 80 80 80 80 80 80 80 80 80 80 80 80 80 80 80 80 80 80 80 80 80 80 80 80 80 80 800 800 0
800 800 80 80 80 80 80 80 80 80 80 80 80 80 80 80 80 80 80 80 80 80 80 80 80 80 80 80 80 80 80 80 80 800 800 0
800 800 800 800 800 800 800 800 800 800 800 800 800 800 800 800 800 800 800 800 800 800 800 800 800 800 800 800 800 800 800 800 800 800 800 0
800 800 800 800 800 800 800 800 800 800 800 800 800 800 800 800 800 800 800 800 800 800 800 800 800 800 800 800 800 800 800 800 800 800 800 0
0 0 0 0 0 0 0 0 0 0 0 0 0 0 0 0 0 0 0 0 0 0 0 0 0 0 0 0 0 0 0 0 0 0 0 0>;

	synaptics,pt05_high_c = /bits/ 16 <
500 700 700 700 700 700 700 700 700 700 700 700 700 700 700 700 700 700 700 700 700 700 700 700 700 700 700 700 700 700 700 700 700 700 700 250
700 700 700 700 700 700 700 700 700 700 700 700 700 700 700 700 700 700 700 700 700 700 700 700 700 700 700 700 700 700 700 700 700 700 700 700
700 700 700 700 700 700 700 700 700 700 700 700 700 700 700 700 700 700 700 700 700 700 700 700 700 700 700 700 700 700 700 700 700 700 700 700
700 700 700 700 700 700 700 700 700 700 700 700 700 700 700 700 700 700 700 700 700 700 700 700 700 700 700 700 700 700 700 700 700 700 700 700
700 700 700 700 700 700 700 700 700 700 700 700 700 700 700 700 700 700 700 700 700 700 700 700 700 700 700 700 700 700 700 700 700 700 700 700
700 700 700 700 700 700 700 700 700 700 700 700 700 700 700 700 700 700 700 700 700 700 700 700 700 700 700 700 700 700 700 700 700 700 700 700
700 700 700 700 700 700 700 700 700 700 700 700 700 700 700 700 700 700 700 700 700 700 700 700 700 700 700 700 700 700 700 700 700 700 700 700
700 700 700 700 700 700 700 700 700 700 700 700 700 700 700 700 700 700 700 700 700 700 700 700 700 700 700 700 700 700 700 700 700 700 700 700
700 700 700 700 700 700 700 700 700 700 700 700 700 700 700 700 700 700 700 700 700 700 700 700 700 700 700 700 700 700 700 700 700 700 700 700
700 700 700 700 700 700 700 700 700 700 700 700 700 700 700 700 700 700 700 700 700 700 700 700 700 700 700 700 700 700 700 700 700 700 700 700
700 700 700 700 700 700 700 700 700 700 700 700 700 700 700 700 700 700 700 700 700 700 700 700 700 700 700 700 700 700 700 700 700 700 700 700
700 700 700 700 700 700 700 700 700 700 700 700 700 700 700 700 700 700 700 700 700 700 700 700 700 700 700 700 700 700 700 700 700 700 700 700
700 700 700 700 700 700 700 700 700 700 700 700 700 700 700 700 700 700 700 700 700 700 700 700 700 700 700 700 700 700 700 700 700 700 700 700
700 700 700 700 700 700 700 700 700 700 700 700 700 700 700 700 700 700 700 700 700 700 700 700 700 700 700 700 700 700 700 700 700 700 700 700
700 700 700 700 700 700 700 700 700 700 700 700 700 700 700 700 700 700 700 700 700 700 700 700 700 700 700 700 700 700 700 700 700 700 700 700
250 700 700 700 700 700 700 700 700 700 700 700 700 700 700 700 700 700 700 700 700 700 700 700 700 700 700 700 700 700 700 700 700 700 700 500>;
	synaptics,pt05_low_c = /bits/ 16 <
100 200 200 200 200 200 200 200 200 200 200 200 200 200 200 200 200 200 200 200 200 200 200 200 200 200 200 200 200 200 200 200 200 200 200 25
200 200 200 200 200 200 200 200 200 200 200 200 200 200 200 200 200 200 200 200 200 200 200 200 200 200 200 200 200 200 200 200 200 200 200 200
200 200 200 200 200 200 200 200 200 200 200 200 200 200 200 200 200 200 200 200 200 200 200 200 200 200 200 200 200 200 200 200 200 200 200 200
200 200 200 200 200 200 200 200 200 200 200 200 200 200 200 200 200 200 200 200 200 200 200 200 200 200 200 200 200 200 200 200 200 200 200 200
200 200 200 200 200 200 200 200 200 200 200 200 200 200 200 200 200 200 200 200 200 200 200 200 200 200 200 200 200 200 200 200 200 200 200 200
200 200 200 200 200 200 200 200 200 200 200 200 200 200 200 200 200 200 200 200 200 200 200 200 200 200 200 200 200 200 200 200 200 200 200 200
200 200 200 200 200 200 200 200 200 200 200 200 200 200 200 200 200 200 200 200 200 200 200 200 200 200 200 200 200 200 200 200 200 200 200 200
200 200 200 200 200 200 200 200 200 200 200 200 200 200 200 200 200 200 200 200 200 200 200 200 200 200 200 200 200 200 200 200 200 200 200 200
200 200 200 200 200 200 200 200 200 200 200 200 200 200 200 200 200 200 200 200 200 200 200 200 200 200 200 200 200 200 200 200 200 200 200 200
200 200 200 200 200 200 200 200 200 200 200 200 200 200 200 200 200 200 200 200 200 200 200 200 200 200 200 200 200 200 200 200 200 200 200 200
200 200 200 200 200 200 200 200 200 200 200 200 200 200 200 200 200 200 200 200 200 200 200 200 200 200 200 200 200 200 200 200 200 200 200 200
200 200 200 200 200 200 200 200 200 200 200 200 200 200 200 200 200 200 200 200 200 200 200 200 200 200 200 200 200 200 200 200 200 200 200 200
200 200 200 200 200 200 200 200 200 200 200 200 200 200 200 200 200 200 200 200 200 200 200 200 200 200 200 200 200 200 200 200 200 200 200 200
200 200 200 200 200 200 200 200 200 200 200 200 200 200 200 200 200 200 200 200 200 200 200 200 200 200 200 200 200 200 200 200 200 200 200 200
200 200 200 200 200 200 200 200 200 200 200 200 200 200 200 200 200 200 200 200 200 200 200 200 200 200 200 200 200 200 200 200 200 200 200 200
25 200 200 200 200 200 200 200 200 200 200 200 200 200 200 200 200 200 200 200 200 200 200 200 200 200 200 200 200 200 200 200 200 200 200 100>;
	synaptics,pt05_gap_x_c = /bits/ 16 <
98 50 35 35 35 35 35 35 35 35 35 35 35 35 35 35 35 35 35 35 35 35 35 35 35 35 35 35 35 35 35 35 35 35 98 98
50 35 32 32 32 32 32 32 32 32 32 32 32 32 32 32 32 32 32 32 32 32 32 32 32 32 32 32 32 32 32 32 32 32 50 60
35 35 32 32 32 32 32 32 32 32 32 32 32 32 32 32 32 32 32 32 32 32 32 32 32 32 32 32 32 32 32 32 32 32 50 35
35 35 32 32 32 32 32 32 32 32 32 32 32 32 32 32 32 32 32 32 32 32 32 32 32 32 32 32 32 32 32 32 32 32 50 35
35 35 32 32 32 32 32 32 32 32 32 32 32 32 32 32 32 32 32 32 32 32 32 32 32 32 32 32 32 32 32 32 32 32 50 35
35 35 32 32 32 32 32 32 32 32 32 32 32 32 32 32 32 32 32 32 32 32 32 32 32 32 32 32 32 32 32 32 32 32 50 35
35 60 32 32 32 32 32 32 32 32 32 32 32 32 32 32 32 32 32 32 32 32 32 32 32 32 32 32 32 32 32 32 32 32 50 35
60 60 35 32 32 32 32 32 32 32 32 32 32 32 32 32 32 32 32 32 32 32 32 32 32 32 32 32 32 32 32 32 32 32 50 35
60 60 35 32 32 32 32 32 32 32 32 32 32 32 32 32 32 32 32 32 32 32 32 32 32 32 32 32 32 32 32 32 32 32 50 35
35 35 32 32 32 32 32 32 32 32 32 32 32 32 32 32 32 32 32 32 32 32 32 32 32 32 32 32 32 32 32 32 32 32 50 35
35 35 32 32 32 32 32 32 32 32 32 32 32 32 32 32 32 32 32 32 32 32 32 32 32 32 32 32 32 32 32 32 32 32 50 35
35 35 32 32 32 32 32 32 32 32 32 32 32 32 32 32 32 32 32 32 32 32 32 32 32 32 32 32 32 32 32 32 32 32 50 35
35 35 32 32 32 32 32 32 32 32 32 32 32 32 32 32 32 32 32 32 32 32 32 32 32 32 32 32 32 32 32 32 32 32 50 35
60 35 32 32 32 32 32 32 32 32 32 32 32 32 32 32 32 32 32 32 32 32 32 32 32 32 32 32 32 32 32 32 32 32 50 60
98 50 35 35 35 35 35 35 35 35 35 35 35 35 35 35 35 35 35 35 35 35 35 35 35 35 35 35 35 35 35 35 35 35 50 60
98 50 32 32 32 32 32 32 32 32 32 32 32 32 32 32 32 32 32 32 32 32 32 32 32 32 32 32 32 32 32 32 32 50 60 35>;

	synaptics,pt0a_high_c = /bits/ 16 <
35  35  35  35  35  35  35  35  35  35  35  35  35  35  35  35  35  35  35  35  35  35  35  35  35  35  35  35  35  35  35  35  35  35  35  35
35  35  35  35  35  35  35  35  35  35  35  35  35  35  35  35  35  35  35  35  35  35  35  35  35  35  35  35  35  35  35  35  35  35  35  35
35  35  35  35  35  35  35  35  35  35  35  35  35  35  35  35  35  35  35  35  35  35  35  35  35  35  35  35  35  35  35  35  35  35  35  35
35  35  35  35  35  35  35  35  35  35  35  35  35  35  35  35  35  35  35  35  35  35  35  35  35  35  35  35  35  35  35  35  35  35  35  35
35  35  35  35  35  35  35  35  35  35  35  35  35  35  35  35  35  35  35  35  35  35  35  35  35  35  35  35  35  35  35  35  35  35  35  35
35  35  35  35  35  35  35  35  35  35  35  35  35  35  35  35  35  35  35  35  35  35  35  35  35  35  35  35  35  35  35  35  35  35  35  35
35  35  35  35  35  35  35  35  35  35  35  35  35  35  35  35  35  35  35  35  35  35  35  35  35  35  35  35  35  35  35  35  35  35  35  35
35  35  35  35  35  35  35  35  35  35  35  35  35  35  35  35  35  35  35  35  35  35  35  35  35  35  35  35  35  35  35  35  35  35  35  35
35  35  35  35  35  35  35  35  35  35  35  35  35  35  35  35  35  35  35  35  35  35  35  35  35  35  35  35  35  35  35  35  35  35  35  35
35  35  35  35  35  35  35  35  35  35  35  35  35  35  35  35  35  35  35  35  35  35  35  35  35  35  35  35  35  35  35  35  35  35  35  35
35  35  35  35  35  35  35  35  35  35  35  35  35  35  35  35  35  35  35  35  35  35  35  35  35  35  35  35  35  35  35  35  35  35  35  35
35  35  35  35  35  35  35  35  35  35  35  35  35  35  35  35  35  35  35  35  35  35  35  35  35  35  35  35  35  35  35  35  35  35  35  35
35  35  35  35  35  35  35  35  35  35  35  35  35  35  35  35  35  35  35  35  35  35  35  35  35  35  35  35  35  35  35  35  35  35  35  35
35  35  35  35  35  35  35  35  35  35  35  35  35  35  35  35  35  35  35  35  35  35  35  35  35  35  35  35  35  35  35  35  35  35  35  35
35  35  35  35  35  35  35  35  35  35  35  35  35  35  35  35  35  35  35  35  35  35  35  35  35  35  35  35  35  35  35  35  35  35  35  35
35  35  35  35  35  35  35  35  35  35  35  35  35  35  35  35  35  35  35  35  35  35  35  35  35  35  35  35  35  35  35  35  35  35  35  35>;
	synaptics,pt0a_low_c = /bits/ 16 <
(-35) (-35) (-35) (-35) (-35) (-35) (-35) (-35) (-35) (-35) (-35) (-35) (-35) (-35) (-35) (-35) (-35) (-35) (-35) (-35) (-35) (-35) (-35) (-35) (-35) (-35) (-35) (-35) (-35) (-35) (-35) (-35) (-35) (-35) (-35) (-35)
(-35) (-35) (-35) (-35) (-35) (-35) (-35) (-35) (-35) (-35) (-35) (-35) (-35) (-35) (-35) (-35) (-35) (-35) (-35) (-35) (-35) (-35) (-35) (-35) (-35) (-35) (-35) (-35) (-35) (-35) (-35) (-35) (-35) (-35) (-35) (-35)
(-35) (-35) (-35) (-35) (-35) (-35) (-35) (-35) (-35) (-35) (-35) (-35) (-35) (-35) (-35) (-35) (-35) (-35) (-35) (-35) (-35) (-35) (-35) (-35) (-35) (-35) (-35) (-35) (-35) (-35) (-35) (-35) (-35) (-35) (-35) (-35)
(-35) (-35) (-35) (-35) (-35) (-35) (-35) (-35) (-35) (-35) (-35) (-35) (-35) (-35) (-35) (-35) (-35) (-35) (-35) (-35) (-35) (-35) (-35) (-35) (-35) (-35) (-35) (-35) (-35) (-35) (-35) (-35) (-35) (-35) (-35) (-35)
(-35) (-35) (-35) (-35) (-35) (-35) (-35) (-35) (-35) (-35) (-35) (-35) (-35) (-35) (-35) (-35) (-35) (-35) (-35) (-35) (-35) (-35) (-35) (-35) (-35) (-35) (-35) (-35) (-35) (-35) (-35) (-35) (-35) (-35) (-35) (-35)
(-35) (-35) (-35) (-35) (-35) (-35) (-35) (-35) (-35) (-35) (-35) (-35) (-35) (-35) (-35) (-35) (-35) (-35) (-35) (-35) (-35) (-35) (-35) (-35) (-35) (-35) (-35) (-35) (-35) (-35) (-35) (-35) (-35) (-35) (-35) (-35)
(-35) (-35) (-35) (-35) (-35) (-35) (-35) (-35) (-35) (-35) (-35) (-35) (-35) (-35) (-35) (-35) (-35) (-35) (-35) (-35) (-35) (-35) (-35) (-35) (-35) (-35) (-35) (-35) (-35) (-35) (-35) (-35) (-35) (-35) (-35) (-35)
(-35) (-35) (-35) (-35) (-35) (-35) (-35) (-35) (-35) (-35) (-35) (-35) (-35) (-35) (-35) (-35) (-35) (-35) (-35) (-35) (-35) (-35) (-35) (-35) (-35) (-35) (-35) (-35) (-35) (-35) (-35) (-35) (-35) (-35) (-35) (-35)
(-35) (-35) (-35) (-35) (-35) (-35) (-35) (-35) (-35) (-35) (-35) (-35) (-35) (-35) (-35) (-35) (-35) (-35) (-35) (-35) (-35) (-35) (-35) (-35) (-35) (-35) (-35) (-35) (-35) (-35) (-35) (-35) (-35) (-35) (-35) (-35)
(-35) (-35) (-35) (-35) (-35) (-35) (-35) (-35) (-35) (-35) (-35) (-35) (-35) (-35) (-35) (-35) (-35) (-35) (-35) (-35) (-35) (-35) (-35) (-35) (-35) (-35) (-35) (-35) (-35) (-35) (-35) (-35) (-35) (-35) (-35) (-35)
(-35) (-35) (-35) (-35) (-35) (-35) (-35) (-35) (-35) (-35) (-35) (-35) (-35) (-35) (-35) (-35) (-35) (-35) (-35) (-35) (-35) (-35) (-35) (-35) (-35) (-35) (-35) (-35) (-35) (-35) (-35) (-35) (-35) (-35) (-35) (-35)
(-35) (-35) (-35) (-35) (-35) (-35) (-35) (-35) (-35) (-35) (-35) (-35) (-35) (-35) (-35) (-35) (-35) (-35) (-35) (-35) (-35) (-35) (-35) (-35) (-35) (-35) (-35) (-35) (-35) (-35) (-35) (-35) (-35) (-35) (-35) (-35)
(-35) (-35) (-35) (-35) (-35) (-35) (-35) (-35) (-35) (-35) (-35) (-35) (-35) (-35) (-35) (-35) (-35) (-35) (-35) (-35) (-35) (-35) (-35) (-35) (-35) (-35) (-35) (-35) (-35) (-35) (-35) (-35) (-35) (-35) (-35) (-35)
(-35) (-35) (-35) (-35) (-35) (-35) (-35) (-35) (-35) (-35) (-35) (-35) (-35) (-35) (-35) (-35) (-35) (-35) (-35) (-35) (-35) (-35) (-35) (-35) (-35) (-35) (-35) (-35) (-35) (-35) (-35) (-35) (-35) (-35) (-35) (-35)
(-35) (-35) (-35) (-35) (-35) (-35) (-35) (-35) (-35) (-35) (-35) (-35) (-35) (-35) (-35) (-35) (-35) (-35) (-35) (-35) (-35) (-35) (-35) (-35) (-35) (-35) (-35) (-35) (-35) (-35) (-35) (-35) (-35) (-35) (-35) (-35)
(-35) (-35) (-35) (-35) (-35) (-35) (-35) (-35) (-35) (-35) (-35) (-35) (-35) (-35) (-35) (-35) (-35) (-35) (-35) (-35) (-35) (-35) (-35) (-35) (-35) (-35) (-35) (-35) (-35) (-35) (-35) (-35) (-35) (-35) (-35) (-35)>;

	synaptics,pt10_high_c = /bits/ 16 <
45  45  45  45  45  45  45  45  45  45  45  45  45  45  45  45  45  45  45  45  45  45  45  45  45  45  45  45  45  45  45  45  45  45  45  45
45  45  45  45  45  45  45  45  45  45  45  45  45  45  45  45  45  45  45  45  45  45  45  45  45  45  45  45  45  45  45  45  45  45  45  45
45  45  45  45  45  45  45  45  45  45  45  45  45  45  45  45  45  45  45  45  45  45  45  45  45  45  45  45  45  45  45  45  45  45  45  45
45  45  45  45  45  45  45  45  45  45  45  45  45  45  45  45  45  45  45  45  45  45  45  45  45  45  45  45  45  45  45  45  45  45  45  45
45  45  45  45  45  45  45  45  45  45  45  45  45  45  45  45  45  45  45  45  45  45  45  45  45  45  45  45  45  45  45  45  45  45  45  45
45  45  45  45  45  45  45  45  45  45  45  45  45  45  45  45  45  45  45  45  45  45  45  45  45  45  45  45  45  45  45  45  45  45  45  45
45  45  45  45  45  45  45  45  45  45  45  45  45  45  45  45  45  45  45  45  45  45  45  45  45  45  45  45  45  45  45  45  45  45  45  45
45  45  45  45  45  45  45  45  45  45  45  45  45  45  45  45  45  45  45  45  45  45  45  45  45  45  45  45  45  45  45  45  45  45  45  45
45  45  45  45  45  45  45  45  45  45  45  45  45  45  45  45  45  45  45  45  45  45  45  45  45  45  45  45  45  45  45  45  45  45  45  45
45  45  45  45  45  45  45  45  45  45  45  45  45  45  45  45  45  45  45  45  45  45  45  45  45  45  45  45  45  45  45  45  45  45  45  45
45  45  45  45  45  45  45  45  45  45  45  45  45  45  45  45  45  45  45  45  45  45  45  45  45  45  45  45  45  45  45  45  45  45  45  45
45  45  45  45  45  45  45  45  45  45  45  45  45  45  45  45  45  45  45  45  45  45  45  45  45  45  45  45  45  45  45  45  45  45  45  45
45  45  45  45  45  45  45  45  45  45  45  45  45  45  45  45  45  45  45  45  45  45  45  45  45  45  45  45  45  45  45  45  45  45  45  45
45  45  45  45  45  45  45  45  45  45  45  45  45  45  45  45  45  45  45  45  45  45  45  45  45  45  45  45  45  45  45  45  45  45  45  45
45  45  45  45  45  45  45  45  45  45  45  45  45  45  45  45  45  45  45  45  45  45  45  45  45  45  45  45  45  45  45  45  45  45  45  45
45  45  45  45  45  45  45  45  45  45  45  45  45  45  45  45  45  45  45  45  45  45  45  45  45  45  45  45  45  45  45  45  45  45  45  45>;
	synaptics,pt10_low_c = /bits/ 16 <
0 0 0 0 0 0 0 0 0 0 0 0 0 0 0 0 0 0 0 0 0 0 0 0 0 0 0 0 0 0 0 0 0 0 0 0
0 0 0 0 0 0 0 0 0 0 0 0 0 0 0 0 0 0 0 0 0 0 0 0 0 0 0 0 0 0 0 0 0 0 0 0
0 0 0 0 0 0 0 0 0 0 0 0 0 0 0 0 0 0 0 0 0 0 0 0 0 0 0 0 0 0 0 0 0 0 0 0
0 0 0 0 0 0 0 0 0 0 0 0 0 0 0 0 0 0 0 0 0 0 0 0 0 0 0 0 0 0 0 0 0 0 0 0
0 0 0 0 0 0 0 0 0 0 0 0 0 0 0 0 0 0 0 0 0 0 0 0 0 0 0 0 0 0 0 0 0 0 0 0
0 0 0 0 0 0 0 0 0 0 0 0 0 0 0 0 0 0 0 0 0 0 0 0 0 0 0 0 0 0 0 0 0 0 0 0
0 0 0 0 0 0 0 0 0 0 0 0 0 0 0 0 0 0 0 0 0 0 0 0 0 0 0 0 0 0 0 0 0 0 0 0
0 0 0 0 0 0 0 0 0 0 0 0 0 0 0 0 0 0 0 0 0 0 0 0 0 0 0 0 0 0 0 0 0 0 0 0
0 0 0 0 0 0 0 0 0 0 0 0 0 0 0 0 0 0 0 0 0 0 0 0 0 0 0 0 0 0 0 0 0 0 0 0
0 0 0 0 0 0 0 0 0 0 0 0 0 0 0 0 0 0 0 0 0 0 0 0 0 0 0 0 0 0 0 0 0 0 0 0
0 0 0 0 0 0 0 0 0 0 0 0 0 0 0 0 0 0 0 0 0 0 0 0 0 0 0 0 0 0 0 0 0 0 0 0
0 0 0 0 0 0 0 0 0 0 0 0 0 0 0 0 0 0 0 0 0 0 0 0 0 0 0 0 0 0 0 0 0 0 0 0
0 0 0 0 0 0 0 0 0 0 0 0 0 0 0 0 0 0 0 0 0 0 0 0 0 0 0 0 0 0 0 0 0 0 0 0
0 0 0 0 0 0 0 0 0 0 0 0 0 0 0 0 0 0 0 0 0 0 0 0 0 0 0 0 0 0 0 0 0 0 0 0
0 0 0 0 0 0 0 0 0 0 0 0 0 0 0 0 0 0 0 0 0 0 0 0 0 0 0 0 0 0 0 0 0 0 0 0
0 0 0 0 0 0 0 0 0 0 0 0 0 0 0 0 0 0 0 0 0 0 0 0 0 0 0 0 0 0 0 0 0 0 0 0>;
	synaptics,pt10_gap_x_c = /bits/ 16 <
45  45  45  45  45  45  45  45  45  45  45  45  45  45  45  45  45  45  45  45  45  45  45  45  45  45  45  45  45  45  45  45  45  45  45  45
45  45  45  45  45  45  45  45  45  45  45  45  45  45  45  45  45  45  45  45  45  45  45  45  45  45  45  45  45  45  45  45  45  45  45  45
45  45  45  45  45  45  45  45  45  45  45  45  45  45  45  45  45  45  45  45  45  45  45  45  45  45  45  45  45  45  45  45  45  45  45  45
45  45  45  45  45  45  45  45  45  45  45  45  45  45  45  45  45  45  45  45  45  45  45  45  45  45  45  45  45  45  45  45  45  45  45  45
45  45  45  45  45  45  45  45  45  45  45  45  45  45  45  45  45  45  45  45  45  45  45  45  45  45  45  45  45  45  45  45  45  45  45  45
45  45  45  45  45  45  45  45  45  45  45  45  45  45  45  45  45  45  45  45  45  45  45  45  45  45  45  45  45  45  45  45  45  45  45  45
45  45  45  45  45  45  45  45  45  45  45  45  45  45  45  45  45  45  45  45  45  45  45  45  45  45  45  45  45  45  45  45  45  45  45  45
45  45  45  45  45  45  45  45  45  45  45  45  45  45  45  45  45  45  45  45  45  45  45  45  45  45  45  45  45  45  45  45  45  45  45  45
45  45  45  45  45  45  45  45  45  45  45  45  45  45  45  45  45  45  45  45  45  45  45  45  45  45  45  45  45  45  45  45  45  45  45  45
45  45  45  45  45  45  45  45  45  45  45  45  45  45  45  45  45  45  45  45  45  45  45  45  45  45  45  45  45  45  45  45  45  45  45  45
45  45  45  45  45  45  45  45  45  45  45  45  45  45  45  45  45  45  45  45  45  45  45  45  45  45  45  45  45  45  45  45  45  45  45  45
45  45  45  45  45  45  45  45  45  45  45  45  45  45  45  45  45  45  45  45  45  45  45  45  45  45  45  45  45  45  45  45  45  45  45  45
45  45  45  45  45  45  45  45  45  45  45  45  45  45  45  45  45  45  45  45  45  45  45  45  45  45  45  45  45  45  45  45  45  45  45  45
45  45  45  45  45  45  45  45  45  45  45  45  45  45  45  45  45  45  45  45  45  45  45  45  45  45  45  45  45  45  45  45  45  45  45  45
45  45  45  45  45  45  45  45  45  45  45  45  45  45  45  45  45  45  45  45  45  45  45  45  45  45  45  45  45  45  45  45  45  45  45  45
45  45  45  45  45  45  45  45  45  45  45  45  45  45  45  45  45  45  45  45  45  45  45  45  45  45  45  45  45  45  45  45  45  45  45  45>;

	synaptics,pt11_high_c = /bits/ 16 <
145 145 145 145 145 145 145 145 145 145 145 145 145 145 145 145 145 145 145 145 145 145 145 145 145 145 145 145 145 145 145 145 145 145 145 145
145 145 145 145 145 145 145 145 145 145 145 145 145 145 145 145 145 145 145 145 145 145 145 145 145 145 145 145 145 145 145 145 145 145 145 145
145 145 145 145 145 145 145 145 145 145 145 145 145 145 145 145 145 145 145 145 145 145 145 145 145 145 145 145 145 145 145 145 145 145 145 145
145 145 145 145 145 145 145 145 145 145 145 145 145 145 145 145 145 145 145 145 145 145 145 145 145 145 145 145 145 145 145 145 145 145 145 145
145 145 145 145 145 145 145 145 145 145 145 145 145 145 145 145 145 145 145 145 145 145 145 145 145 145 145 145 145 145 145 145 145 145 145 145
145 145 145 145 145 145 145 145 145 145 145 145 145 145 145 145 145 145 145 145 145 145 145 145 145 145 145 145 145 145 145 145 145 145 145 145
145 145 145 145 145 145 145 145 145 145 145 145 145 145 145 145 145 145 145 145 145 145 145 145 145 145 145 145 145 145 145 145 145 145 145 145
145 145 145 145 145 145 145 145 145 145 145 145 145 145 145 145 145 145 145 145 145 145 145 145 145 145 145 145 145 145 145 145 145 145 145 145
145 145 145 145 145 145 145 145 145 145 145 145 145 145 145 145 145 145 145 145 145 145 145 145 145 145 145 145 145 145 145 145 145 145 145 145
145 145 145 145 145 145 145 145 145 145 145 145 145 145 145 145 145 145 145 145 145 145 145 145 145 145 145 145 145 145 145 145 145 145 145 145
145 145 145 145 145 145 145 145 145 145 145 145 145 145 145 145 145 145 145 145 145 145 145 145 145 145 145 145 145 145 145 145 145 145 145 145
145 145 145 145 145 145 145 145 145 145 145 145 145 145 145 145 145 145 145 145 145 145 145 145 145 145 145 145 145 145 145 145 145 145 145 145
145 145 145 145 145 145 145 145 145 145 145 145 145 145 145 145 145 145 145 145 145 145 145 145 145 145 145 145 145 145 145 145 145 145 145 145
145 145 145 145 145 145 145 145 145 145 145 145 145 145 145 145 145 145 145 145 145 145 145 145 145 145 145 145 145 145 145 145 145 145 145 145
145 145 145 145 145 145 145 145 145 145 145 145 145 145 145 145 145 145 145 145 145 145 145 145 145 145 145 145 145 145 145 145 145 145 145 145
145 145 145 145 145 145 145 145 145 145 145 145 145 145 145 145 145 145 145 145 145 145 145 145 145 145 145 145 145 145 145 145 145 145 145 145>;
	synaptics,pt11_low_c = /bits/ 16 <
95 95 95 95 95 95 95 95 95 95 95 95 95 95 95 95 95 95 95 95 95 95 95 95 95 95 95 95 95 95 95 95 95 95 95 95
95 95 95 95 95 95 95 95 95 95 95 95 95 95 95 95 95 95 95 95 95 95 95 95 95 95 95 95 95 95 95 95 95 95 95 95
95 95 95 95 95 95 95 95 95 95 95 95 95 95 95 95 95 95 95 95 95 95 95 95 95 95 95 95 95 95 95 95 95 95 95 95
95 95 95 95 95 95 95 95 95 95 95 95 95 95 95 95 95 95 95 95 95 95 95 95 95 95 95 95 95 95 95 95 95 95 95 95
95 95 95 95 95 95 95 95 95 95 95 95 95 95 95 95 95 95 95 95 95 95 95 95 95 95 95 95 95 95 95 95 95 95 95 95
95 95 95 95 95 95 95 95 95 95 95 95 95 95 95 95 95 95 95 95 95 95 95 95 95 95 95 95 95 95 95 95 95 95 95 95
95 95 95 95 95 95 95 95 95 95 95 95 95 95 95 95 95 95 95 95 95 95 95 95 95 95 95 95 95 95 95 95 95 95 95 95
95 95 95 95 95 95 95 95 95 95 95 95 95 95 95 95 95 95 95 95 95 95 95 95 95 95 95 95 95 95 95 95 95 95 95 95
95 95 95 95 95 95 95 95 95 95 95 95 95 95 95 95 95 95 95 95 95 95 95 95 95 95 95 95 95 95 95 95 95 95 95 95
95 95 95 95 95 95 95 95 95 95 95 95 95 95 95 95 95 95 95 95 95 95 95 95 95 95 95 95 95 95 95 95 95 95 95 95
95 95 95 95 95 95 95 95 95 95 95 95 95 95 95 95 95 95 95 95 95 95 95 95 95 95 95 95 95 95 95 95 95 95 95 95
95 95 95 95 95 95 95 95 95 95 95 95 95 95 95 95 95 95 95 95 95 95 95 95 95 95 95 95 95 95 95 95 95 95 95 95
95 95 95 95 95 95 95 95 95 95 95 95 95 95 95 95 95 95 95 95 95 95 95 95 95 95 95 95 95 95 95 95 95 95 95 95
95 95 95 95 95 95 95 95 95 95 95 95 95 95 95 95 95 95 95 95 95 95 95 95 95 95 95 95 95 95 95 95 95 95 95 95
95 95 95 95 95 95 95 95 95 95 95 95 95 95 95 95 95 95 95 95 95 95 95 95 95 95 95 95 95 95 95 95 95 95 95 95
95 95 95 95 95 95 95 95 95 95 95 95 95 95 95 95 95 95 95 95 95 95 95 95 95 95 95 95 95 95 95 95 95 95 95 95>;

	synaptics,pt12_high_c = <
270000 270000 270000 270000 270000 270000 270000 270000 270000 270000 270000 270000 270000 270000 270000 270000 270000 270000 270000 270000 270000 270000 270000 270000 270000 270000 270000 270000 270000 270000 270000 270000 270000 270000 270000 270000 380000 380000 380000 380000 380000 380000 380000 380000 380000 380000 380000 380000 380000 380000 380000 380000>;
	synaptics,pt12_low_c = <
170000 170000 170000 170000 170000 170000 170000 170000 170000 170000 170000 170000 170000 170000 170000 170000 170000 170000 170000 170000 170000 170000 170000 170000 170000 170000 170000 170000 170000 170000 170000 170000 170000 170000 170000 170000 270000 270000 270000 270000 270000 270000 270000 270000 270000 270000 270000 270000 270000 270000 270000 270000>;

	synaptics,pt16_high_c = /bits/ 16 <
500 800 800 800 800 800 800 800 800 800 800 800 800 800 800 800 800 800 800 800 800 800 800 800 800 800 800 800 800 800 800 800 800 800 800 250
800 800 800 800 800 800 800 800 800 800 800 800 800 800 800 800 800 800 800 800 800 800 800 800 800 800 800 800 800 800 800 800 800 800 800 800
800 800 800 800 800 800 800 800 800 800 800 800 800 800 800 800 800 800 800 800 800 800 800 800 800 800 800 800 800 800 800 800 800 800 800 800
800 800 800 800 800 800 800 800 800 800 800 800 800 800 800 800 800 800 800 800 800 800 800 800 800 800 800 800 800 800 800 800 800 800 800 800
800 800 800 800 800 800 800 800 800 800 800 800 800 800 800 800 800 800 800 800 800 800 800 800 800 800 800 800 800 800 800 800 800 800 800 800
800 800 800 800 800 800 800 800 800 800 800 800 800 800 800 800 800 800 800 800 800 800 800 800 800 800 800 800 800 800 800 800 800 800 800 800
800 800 800 800 800 800 800 800 800 800 800 800 800 800 800 800 800 800 800 800 800 800 800 800 800 800 800 800 800 800 800 800 800 800 800 800
800 800 800 800 800 800 800 800 800 800 800 800 800 800 800 800 800 800 800 800 800 800 800 800 800 800 800 800 800 800 800 800 800 800 800 800
800 800 800 800 800 800 800 800 800 800 800 800 800 800 800 800 800 800 800 800 800 800 800 800 800 800 800 800 800 800 800 800 800 800 800 800
800 800 800 800 800 800 800 800 800 800 800 800 800 800 800 800 800 800 800 800 800 800 800 800 800 800 800 800 800 800 800 800 800 800 800 800
800 800 800 800 800 800 800 800 800 800 800 800 800 800 800 800 800 800 800 800 800 800 800 800 800 800 800 800 800 800 800 800 800 800 800 800
800 800 800 800 800 800 800 800 800 800 800 800 800 800 800 800 800 800 800 800 800 800 800 800 800 800 800 800 800 800 800 800 800 800 800 800
800 800 800 800 800 800 800 800 800 800 800 800 800 800 800 800 800 800 800 800 800 800 800 800 800 800 800 800 800 800 800 800 800 800 800 800
800 800 800 800 800 800 800 800 800 800 800 800 800 800 800 800 800 800 800 800 800 800 800 800 800 800 800 800 800 800 800 800 800 800 800 800
800 800 800 800 800 800 800 800 800 800 800 800 800 800 800 800 800 800 800 800 800 800 800 800 800 800 800 800 800 800 800 800 800 800 800 800
250 800 800 800 800 800 800 800 800 800 800 800 800 800 800 800 800 800 800 800 800 800 800 800 800 800 800 800 800 800 800 800 800 800 800 500>;
	synaptics,pt16_low_c = /bits/ 16 <
150 200 200 200 200 200 200 200 200 200 200 200 200 200 200 200 200 200 200 200 200 200 200 200 200 200 200 200 200 200 200 200 200 200 200 50
200 200 200 200 200 200 200 200 200 200 200 200 200 200 200 200 200 200 200 200 200 200 200 200 200 200 200 200 200 200 200 200 200 200 200 200
200 200 200 200 200 200 200 200 200 200 200 200 200 200 200 200 200 200 200 200 200 200 200 200 200 200 200 200 200 200 200 200 200 200 200 200
200 200 200 200 200 200 200 200 200 200 200 200 200 200 200 200 200 200 200 200 200 200 200 200 200 200 200 200 200 200 200 200 200 200 200 200
200 200 200 200 200 200 200 200 200 200 200 200 200 200 200 200 200 200 200 200 200 200 200 200 200 200 200 200 200 200 200 200 200 200 200 200
200 200 200 200 200 200 200 200 200 200 200 200 200 200 200 200 200 200 200 200 200 200 200 200 200 200 200 200 200 200 200 200 200 200 200 200
200 200 200 200 200 200 200 200 200 200 200 200 200 200 200 200 200 200 200 200 200 200 200 200 200 200 200 200 200 200 200 200 200 200 200 200
200 200 200 200 200 200 200 200 200 200 200 200 200 200 200 200 200 200 200 200 200 200 200 200 200 200 200 200 200 200 200 200 200 200 200 200
200 200 200 200 200 200 200 200 200 200 200 200 200 200 200 200 200 200 200 200 200 200 200 200 200 200 200 200 200 200 200 200 200 200 200 200
200 200 200 200 200 200 200 200 200 200 200 200 200 200 200 200 200 200 200 200 200 200 200 200 200 200 200 200 200 200 200 200 200 200 200 200
200 200 200 200 200 200 200 200 200 200 200 200 200 200 200 200 200 200 200 200 200 200 200 200 200 200 200 200 200 200 200 200 200 200 200 200
200 200 200 200 200 200 200 200 200 200 200 200 200 200 200 200 200 200 200 200 200 200 200 200 200 200 200 200 200 200 200 200 200 200 200 200
200 200 200 200 200 200 200 200 200 200 200 200 200 200 200 200 200 200 200 200 200 200 200 200 200 200 200 200 200 200 200 200 200 200 200 200
200 200 200 200 200 200 200 200 200 200 200 200 200 200 200 200 200 200 200 200 200 200 200 200 200 200 200 200 200 200 200 200 200 200 200 200
200 200 200 200 200 200 200 200 200 200 200 200 200 200 200 200 200 200 200 200 200 200 200 200 200 200 200 200 200 200 200 200 200 200 200 200
40 200 200 200 200 200 200 200 200 200 200 200 200 200 200 200 200 200 200 200 200 200 200 200 200 200 200 200 200 200 200 200 200 200 200 150>;

	synaptics,pt_tag_moisture_c = /bits/ 16 <
600 600 600 600 600 600 600 600 600 600 600 600 600 600 600 600 600 600 600 600 600 600 600 600 600 600 600 600 600 600 600 600 600 600 600 0
600 600 600 600 600 600 600 600 600 600 600 600 600 600 600 600 600 600 600 600 600 600 600 600 600 600 600 600 600 600 600 600 600 600 600 0
600 600 600 600 600 600 600 600 600 600 600 600 600 600 600 600 600 600 600 600 600 600 600 600 600 600 600 600 600 600 600 600 600 600 600 0
600 600 600 600 600 600 600 600 600 600 600 600 600 600 600 600 600 600 600 600 600 600 600 600 600 600 600 600 600 600 600 600 600 600 600 0
600 600 600 600 600 600 600 600 600 600 600 600 600 600 600 600 600 600 600 600 600 600 600 600 600 600 600 600 600 600 600 600 600 600 600 0
600 600 600 600 600 600 600 600 600 600 600 600 600 600 600 600 600 600 600 600 600 600 600 600 600 600 600 600 600 600 600 600 600 600 600 0
600 600 600 600 600 600 600 600 600 600 600 600 600 600 600 600 600 600 600 600 600 600 600 600 600 600 600 600 600 600 600 600 600 600 600 0
600 600 600 600 600 600 600 600 600 600 600 600 600 600 600 600 600 600 600 600 600 600 600 600 600 600 600 600 600 600 600 600 600 600 600 0
600 600 600 600 600 600 600 600 600 600 600 600 600 600 600 600 600 600 600 600 600 600 600 600 600 600 600 600 600 600 600 600 600 600 600 0
600 600 600 600 600 600 600 600 600 600 600 600 600 600 600 600 600 600 600 600 600 600 600 600 600 600 600 600 600 600 600 600 600 600 600 0
600 600 600 600 600 600 600 600 600 600 600 600 600 600 600 600 600 600 600 600 600 600 600 600 600 600 600 600 600 600 600 600 600 600 600 0
600 600 600 600 600 600 600 600 600 600 600 600 600 600 600 600 600 600 600 600 600 600 600 600 600 600 600 600 600 600 600 600 600 600 600 0
600 600 600 600 600 600 600 600 600 600 600 600 600 600 600 600 600 600 600 600 600 600 600 600 600 600 600 600 600 600 600 600 600 600 600 0
600 600 600 600 600 600 600 600 600 600 600 600 600 600 600 600 600 600 600 600 600 600 600 600 600 600 600 600 600 600 600 600 600 600 600 0
600 600 600 600 600 600 600 600 600 600 600 600 600 600 600 600 600 600 600 600 600 600 600 600 600 600 600 600 600 600 600 600 600 600 600 0
0 0 0 0 0 0 0 0 0 0 0 0 0 0 0 0 0 0 0 0 0 0 0 0 0 0 0 0 0 0 0 0 0 0 0 0>;

	/*ical limit */
	synaptics,pt05_high_b_ical = /bits/ 16 <
299 1085 1268 1268 1263 1259 1256 1254 1253 1253 1250 1244 1242 1244 1248 1253 1265 1284 1131 1131 1133 1131 1130 1163 1130 1130 1130 1130 1130 1128 1127 1140 1130 1127 980 249
885 1298 1290 1302 1286 1275 1274 1274 1274 1272 1272 1295 1265 1262 1265 1265 1265 1266 1262 1260 1262 1262 1262 1259 1260 1260 1260 1260 1262 1259 1256 1257 1259 1262 1265 968
1016 1295 1198 1194 1189 1186 1184 1184 1184 1183 1183 1183 1175 1175 1176 1176 1177 1176 1173 1173 1173 1175 1175 1170 1173 1173 1173 1173 1173 1172 1169 1169 1172 1175 1262 1083
1014 1295 1198 1203 1189 1186 1183 1183 1184 1183 1182 1201 1175 1173 1175 1175 1175 1173 1175 1173 1173 1175 1175 1172 1173 1173 1173 1173 1175 1172 1169 1170 1172 1175 1262 1080
1014 1295 1198 1193 1187 1184 1183 1183 1184 1183 1183 1177 1175 1173 1175 1175 1175 1173 1175 1173 1175 1175 1175 1172 1173 1173 1173 1173 1175 1172 1169 1170 1172 1175 1263 1092
1014 1295 1198 1193 1189 1186 1183 1183 1186 1183 1182 1177 1175 1173 1175 1175 1175 1173 1175 1175 1175 1175 1175 1172 1173 1173 1173 1173 1175 1172 1169 1170 1173 1176 1263 1101
1014 1295 1200 1194 1189 1184 1183 1183 1183 1182 1182 1177 1175 1173 1175 1173 1173 1173 1173 1173 1175 1175 1173 1170 1173 1173 1173 1173 1173 1170 1169 1170 1172 1175 1263 1107
1036 805 1294 1196 1187 1183 1182 1182 1183 1182 1182 1176 1173 1172 1173 1172 1172 1173 1173 1172 1173 1173 1173 1170 1172 1172 1172 1172 1173 1170 1169 1169 1172 1175 1262 1116
1033 817 1304 1194 1187 1183 1182 1180 1182 1182 1180 1175 1172 1170 1172 1172 1172 1170 1173 1172 1173 1173 1173 1170 1172 1172 1172 1172 1173 1170 1169 1170 1172 1175 1263 1125
1013 1295 1200 1191 1187 1183 1180 1180 1182 1180 1180 1175 1172 1170 1172 1172 1170 1170 1173 1172 1173 1173 1173 1169 1172 1172 1172 1172 1173 1170 1169 1169 1172 1173 1262 1109
1013 1293 1197 1190 1186 1183 1180 1180 1182 1180 1180 1175 1172 1170 1172 1172 1170 1170 1173 1172 1173 1173 1173 1172 1172 1172 1172 1172 1173 1170 1169 1176 1172 1173 1262 1100
1011 1292 1196 1190 1186 1183 1180 1180 1182 1180 1180 1175 1172 1170 1172 1172 1172 1170 1175 1173 1173 1175 1173 1170 1172 1172 1172 1172 1173 1170 1168 1169 1172 1173 1262 1094
1011 1290 1194 1189 1184 1182 1180 1180 1182 1180 1179 1175 1172 1170 1172 1170 1170 1170 1173 1173 1173 1175 1173 1170 1172 1172 1172 1172 1172 1170 1168 1170 1172 1173 1260 1085
1008 1290 1193 1189 1184 1182 1179 1179 1180 1179 1179 1173 1170 1169 1170 1170 1170 1169 1173 1173 1173 1175 1173 1170 1172 1172 1173 1172 1173 1170 1168 1169 1172 1173 1262 1101
864 1289 1281 1275 1269 1266 1265 1266 1266 1265 1265 1259 1256 1254 1256 1256 1256 1254 1260 1259 1260 1260 1260 1257 1259 1259 1259 1259 1259 1257 1254 1256 1257 1260 1265 963
170 984 1179 1179 1176 1173 1172 1173 1172 1172 1170 1166 1163 1161 1163 1163 1163 1163 1224 1220 1218 1217 1214 1215 1215 1215 1212 1212 1209 1211 1206 1206 1208 1194 1068 342>;
	synaptics,pt05_low_b_ical = /bits/ 16 <
22 104 122 122 121 121 120 120 120 120 120 119 119 119 120 120 121 123 108 108 108 108 108 111 108 108 108 108 108 108 108 109 108 108 93 17
84 124 124 125 123 122 122 122 122 122 122 124 121 121 121 121 121 121 121 121 121 121 121 121 121 121 121 121 121 120 120 120 121 121 121 92
97 124 123 123 122 122 122 122 122 122 122 122 121 121 121 121 121 121 121 121 121 121 121 121 121 121 121 121 121 120 120 120 120 120 121 104
97 124 123 124 122 122 122 122 122 122 122 124 121 121 121 121 121 121 121 121 121 121 121 121 121 121 121 121 121 120 120 120 121 121 121 103
97 124 123 123 122 122 122 122 122 122 122 121 121 121 121 121 121 121 121 121 121 121 121 121 121 121 121 121 121 120 120 120 121 121 121 104
97 124 123 123 122 122 122 122 122 122 122 121 121 121 121 121 121 121 121 121 121 121 121 121 121 121 121 121 121 121 120 120 121 121 121 105
97 124 123 123 122 122 122 122 122 122 122 121 121 121 121 121 121 121 121 121 121 121 121 121 121 121 121 121 121 120 120 120 121 120 121 106
90 70 120 123 122 122 122 122 122 122 122 121 121 121 121 121 121 121 121 121 121 121 121 120 121 121 121 121 121 120 120 120 120 120 121 107
90 72 121 123 122 122 122 122 122 121 122 121 121 121 121 121 121 121 121 121 121 121 121 121 121 121 121 121 121 120 120 120 120 120 121 107
97 124 123 123 122 122 122 122 122 121 121 121 121 121 121 121 121 121 121 121 121 121 121 121 121 121 121 121 121 120 120 120 120 120 120 106
97 124 123 122 122 122 122 122 122 121 121 121 121 121 121 121 121 121 121 121 121 121 121 121 121 121 121 121 121 120 120 121 120 120 120 105
97 124 123 122 122 122 122 122 122 121 121 121 121 121 121 121 121 121 121 121 121 121 121 121 121 121 121 121 121 120 120 120 120 120 121 104
97 124 123 122 122 122 122 122 121 121 121 121 120 120 121 121 120 121 121 121 121 121 121 120 121 121 121 121 121 120 120 120 121 120 121 104
96 123 123 122 122 121 121 121 121 121 121 121 120 120 120 120 120 120 121 121 121 121 121 120 121 121 121 120 121 120 120 120 120 120 121 105
82 123 123 122 122 121 121 121 121 121 121 120 120 120 120 120 120 120 121 121 121 121 121 120 120 121 120 120 121 120 120 120 120 120 121 92
11 94 112 112 112 112 112 112 112 112 112 111 111 111 111 111 111 111 117 117 117 116 116 116 117 116 116 116 115 116 115 115 115 114 102 24>;
	synaptics,pt05_gap_x_b_ical = /bits/ 16 <
442 400 400 400 400 400 400 400 400 400 400 400 400 400 400 400 400 400 400 400 400 400 400 400 400 400 400 400 400 400 400 400 400 400 183
400 400 400 400 400 400 400 400 400 400 400 400 400 400 400 400 400 400 400 400 400 400 400 400 400 400 400 400 400 400 400 400 400 400 400
400 400 400 400 400 400 400 400 400 400 400 400 400 400 400 400 400 400 400 400 400 400 400 400 400 400 400 400 400 400 400 400 400 400 400
400 400 400 400 400 400 400 400 400 400 400 400 400 400 400 400 400 400 400 400 400 400 400 400 400 400 400 400 400 400 400 400 400 400 400
400 400 400 400 400 400 400 400 400 400 400 400 400 400 400 400 400 400 400 400 400 400 400 400 400 400 400 400 400 400 400 400 400 400 400
400 400 400 400 400 400 400 400 400 400 400 400 400 400 400 400 400 400 400 400 400 400 400 400 400 400 400 400 400 400 400 400 400 400 400
400 400 400 400 400 400 400 400 400 400 400 400 400 400 400 400 400 400 400 400 400 400 400 400 400 400 400 400 400 400 400 400 400 400 400
400 400 400 400 400 400 400 400 400 400 400 400 400 400 400 400 400 400 400 400 400 400 400 400 400 400 400 400 400 400 400 400 400 400 400
400 400 400 400 400 400 400 400 400 400 400 400 400 400 400 400 400 400 400 400 400 400 400 400 400 400 400 400 400 400 400 400 400 400 400
400 400 400 400 400 400 400 400 400 400 400 400 400 400 400 400 400 400 400 400 400 400 400 400 400 400 400 400 400 400 400 400 400 400 400
400 400 400 400 400 400 400 400 400 400 400 400 400 400 400 400 400 400 400 400 400 400 400 400 400 400 400 400 400 400 400 400 400 400 400
400 400 400 400 400 400 400 400 400 400 400 400 400 400 400 400 400 400 400 400 400 400 400 400 400 400 400 400 400 400 400 400 400 400 400
400 400 400 400 400 400 400 400 400 400 400 400 400 400 400 400 400 400 400 400 400 400 400 400 400 400 400 400 400 400 400 400 400 400 400
400 400 400 400 400 400 400 400 400 400 400 400 400 400 400 400 400 400 400 400 400 400 400 400 400 400 400 400 400 400 400 400 400 400 400
400 400 400 400 400 400 400 400 400 400 400 400 400 400 400 400 400 400 400 400 400 400 400 400 400 400 400 400 400 400 400 400 400 400 400
993 400 400 400 400 400 400 400 400 400 400 400 400 400 400 400 400 400 400 400 400 400 400 400 400 400 400 400 400 400 400 400 400 400 176>;
	synaptics,pt05_gap_y_b_ical = /bits/ 16 <
351 400 400 400 400 400 400 400 400 400 400 400 400 400 400 400 400 400 400 400 400 400 400 400 400 400 400 400 400 400 400 400 400 400 400 557
400 400 400 400 400 400 400 400 400 400 400 400 400 400 400 400 400 400 400 400 400 400 400 400 400 400 400 400 400 400 400 400 400 400 400 400
400 400 400 400 400 400 400 400 400 400 400 400 400 400 400 400 400 400 400 400 400 400 400 400 400 400 400 400 400 400 400 400 400 400 400 400
400 400 400 400 400 400 400 400 400 400 400 400 400 400 400 400 400 400 400 400 400 400 400 400 400 400 400 400 400 400 400 400 400 400 400 400
400 400 400 400 400 400 400 400 400 400 400 400 400 400 400 400 400 400 400 400 400 400 400 400 400 400 400 400 400 400 400 400 400 400 400 400
400 400 400 400 400 400 400 400 400 400 400 400 400 400 400 400 400 400 400 400 400 400 400 400 400 400 400 400 400 400 400 400 400 400 400 400
400 400 400 400 400 400 400 400 400 400 400 400 400 400 400 400 400 400 400 400 400 400 400 400 400 400 400 400 400 400 400 400 400 400 400 400
400 400 400 400 400 400 400 400 400 400 400 400 400 400 400 400 400 400 400 400 400 400 400 400 400 400 400 400 400 400 400 400 400 400 400 400
400 400 400 400 400 400 400 400 400 400 400 400 400 400 400 400 400 400 400 400 400 400 400 400 400 400 400 400 400 400 400 400 400 400 400 400
400 400 400 400 400 400 400 400 400 400 400 400 400 400 400 400 400 400 400 400 400 400 400 400 400 400 400 400 400 400 400 400 400 400 400 400
400 400 400 400 400 400 400 400 400 400 400 400 400 400 400 400 400 400 400 400 400 400 400 400 400 400 400 400 400 400 400 400 400 400 400 400
400 400 400 400 400 400 400 400 400 400 400 400 400 400 400 400 400 400 400 400 400 400 400 400 400 400 400 400 400 400 400 400 400 400 400 400
400 400 400 400 400 400 400 400 400 400 400 400 400 400 400 400 400 400 400 400 400 400 400 400 400 400 400 400 400 400 400 400 400 400 400 400
400 400 400 400 400 400 400 400 400 400 400 400 400 400 400 400 400 400 400 400 400 400 400 400 400 400 400 400 400 400 400 400 400 400 400 400
189 400 400 400 400 400 400 400 400 400 400 400 400 400 400 400 400 400 400 400 400 400 400 400 400 400 400 400 400 400 400 400 400 400 400 173>;

	synaptics,pt12_high_b_ical = <
264071 279905 283494 282022 280898 280434 280450 279179 278808 278578 277855 277564 278340 278609 278015 277435 277728 276460 286793 286375 286084 285544 285480 284563 285377 285102 285024 284560 284375 283691 283860 283596 283453 283218 281905 259043 605791 615326 616849 616376 616352 616944 616291 616769 625727 627593 628378 626902 626198 626929 626116 612734>;
	synaptics,pt12_low_b_ical = <
105628 111962 113397 112808 112358 112173 112179 111671 111522 111430 111142 111025 111335 111443 111206 110974 111090 110583 114717 114550 114433 114217 114191 113825 114150 114040 114009 113823 113750 113475 113543 113438 113381 113286 112762 103616 242316 246130 246739 246550 246540 246777 246516 246707 250290 251037 251350 250760 250479 250771 250446 245094>;

	synaptics,pt05_high_c_ical = /bits/ 16 <
600 840 840 840 840 840 840 840 840 840 840 840 840 840 840 840 840 840 840 840 840 840 840 840 840 840 840 840 840 840 840 840 840 840 840 300
840 840 840 840 840 840 840 840 840 840 840 840 840 840 840 840 840 840 840 840 840 840 840 840 840 840 840 840 840 840 840 840 840 840 840 840
840 840 840 840 840 840 840 840 840 840 840 840 840 840 840 840 840 840 840 840 840 840 840 840 840 840 840 840 840 840 840 840 840 840 840 840
840 840 840 840 840 840 840 840 840 840 840 840 840 840 840 840 840 840 840 840 840 840 840 840 840 840 840 840 840 840 840 840 840 840 840 840
840 840 840 840 840 840 840 840 840 840 840 840 840 840 840 840 840 840 840 840 840 840 840 840 840 840 840 840 840 840 840 840 840 840 840 840
840 840 840 840 840 840 840 840 840 840 840 840 840 840 840 840 840 840 840 840 840 840 840 840 840 840 840 840 840 840 840 840 840 840 840 840
840 840 840 840 840 840 840 840 840 840 840 840 840 840 840 840 840 840 840 840 840 840 840 840 840 840 840 840 840 840 840 840 840 840 840 840
840 840 840 840 840 840 840 840 840 840 840 840 840 840 840 840 840 840 840 840 840 840 840 840 840 840 840 840 840 840 840 840 840 840 840 840
840 840 840 840 840 840 840 840 840 840 840 840 840 840 840 840 840 840 840 840 840 840 840 840 840 840 840 840 840 840 840 840 840 840 840 840
840 840 840 840 840 840 840 840 840 840 840 840 840 840 840 840 840 840 840 840 840 840 840 840 840 840 840 840 840 840 840 840 840 840 840 840
840 840 840 840 840 840 840 840 840 840 840 840 840 840 840 840 840 840 840 840 840 840 840 840 840 840 840 840 840 840 840 840 840 840 840 840
840 840 840 840 840 840 840 840 840 840 840 840 840 840 840 840 840 840 840 840 840 840 840 840 840 840 840 840 840 840 840 840 840 840 840 840
840 840 840 840 840 840 840 840 840 840 840 840 840 840 840 840 840 840 840 840 840 840 840 840 840 840 840 840 840 840 840 840 840 840 840 840
840 840 840 840 840 840 840 840 840 840 840 840 840 840 840 840 840 840 840 840 840 840 840 840 840 840 840 840 840 840 840 840 840 840 840 840
840 840 840 840 840 840 840 840 840 840 840 840 840 840 840 840 840 840 840 840 840 840 840 840 840 840 840 840 840 840 840 840 840 840 840 840
300 840 840 840 840 840 840 840 840 840 840 840 840 840 840 840 840 840 840 840 840 840 840 840 840 840 840 840 840 840 840 840 840 840 840 600>;
	synaptics,pt05_low_c_ical = /bits/ 16 <
50 100 100 100 100 100 100 100 100 100 100 100 100 100 100 100 100 100 100 100 100 100 100 100 100 100 100 100 100 100 100 100 100 100 100 13
100 100 100 100 100 100 100 100 100 100 100 100 100 100 100 100 100 100 100 100 100 100 100 100 100 100 100 100 100 100 100 100 100 100 100 100
100 100 100 100 100 100 100 100 100 100 100 100 100 100 100 100 100 100 100 100 100 100 100 100 100 100 100 100 100 100 100 100 100 100 100 100
100 100 100 100 100 100 100 100 100 100 100 100 100 100 100 100 100 100 100 100 100 100 100 100 100 100 100 100 100 100 100 100 100 100 100 100
100 100 100 100 100 100 100 100 100 100 100 100 100 100 100 100 100 100 100 100 100 100 100 100 100 100 100 100 100 100 100 100 100 100 100 100
100 100 100 100 100 100 100 100 100 100 100 100 100 100 100 100 100 100 100 100 100 100 100 100 100 100 100 100 100 100 100 100 100 100 100 100
100 100 100 100 100 100 100 100 100 100 100 100 100 100 100 100 100 100 100 100 100 100 100 100 100 100 100 100 100 100 100 100 100 100 100 100
100 100 100 100 100 100 100 100 100 100 100 100 100 100 100 100 100 100 100 100 100 100 100 100 100 100 100 100 100 100 100 100 100 100 100 100
100 100 100 100 100 100 100 100 100 100 100 100 100 100 100 100 100 100 100 100 100 100 100 100 100 100 100 100 100 100 100 100 100 100 100 100
100 100 100 100 100 100 100 100 100 100 100 100 100 100 100 100 100 100 100 100 100 100 100 100 100 100 100 100 100 100 100 100 100 100 100 100
100 100 100 100 100 100 100 100 100 100 100 100 100 100 100 100 100 100 100 100 100 100 100 100 100 100 100 100 100 100 100 100 100 100 100 100
100 100 100 100 100 100 100 100 100 100 100 100 100 100 100 100 100 100 100 100 100 100 100 100 100 100 100 100 100 100 100 100 100 100 100 100
100 100 100 100 100 100 100 100 100 100 100 100 100 100 100 100 100 100 100 100 100 100 100 100 100 100 100 100 100 100 100 100 100 100 100 100
100 100 100 100 100 100 100 100 100 100 100 100 100 100 100 100 100 100 100 100 100 100 100 100 100 100 100 100 100 100 100 100 100 100 100 100
100 100 100 100 100 100 100 100 100 100 100 100 100 100 100 100 100 100 100 100 100 100 100 100 100 100 100 100 100 100 100 100 100 100 100 100
13 100 100 100 100 100 100 100 100 100 100 100 100 100 100 100 100 100 100 100 100 100 100 100 100 100 100 100 100 100 100 100 100 100 100 50>;
	synaptics,pt05_gap_x_c_ical = /bits/ 16 <
95 60 45 45 45 45 45 45 45 45 45 45 45 45 45 45 45 45 45 45 45 45 45 45 45 45 45 45 45 45 45 45 45 45 95 95
75 45 42 42 42 42 42 42 42 42 42 42 42 42 42 42 42 42 42 42 42 42 42 42 42 42 42 42 42 42 42 42 42 42 75 75
45 45 42 42 42 42 42 42 42 42 42 42 42 42 42 42 42 42 42 42 42 42 42 42 42 42 42 42 42 42 42 42 42 42 60 45
45 45 42 42 42 42 42 42 42 42 42 42 42 42 42 42 42 42 42 42 42 42 42 42 42 42 42 42 42 42 42 42 42 42 60 45
45 45 42 42 42 42 42 42 42 42 42 42 42 42 42 42 42 42 42 42 42 42 42 42 42 42 42 42 42 42 42 42 42 42 60 45
45 45 42 42 42 42 42 42 42 42 42 42 42 42 42 42 42 42 42 42 42 42 42 42 42 42 42 42 42 42 42 42 42 42 60 45
45 60 42 42 42 42 42 42 42 42 42 42 42 42 42 42 42 42 42 42 42 42 42 42 42 42 42 42 42 42 42 42 42 42 60 45
60 60 42 42 42 42 42 42 42 42 42 42 42 42 42 42 42 42 42 42 42 42 42 42 42 42 42 42 42 42 42 42 42 42 60 45
60 60 42 42 42 42 42 42 42 42 42 42 42 42 42 42 42 42 42 42 42 42 42 42 42 42 42 42 42 42 42 42 42 42 60 45
45 45 42 42 42 42 42 42 42 42 42 42 42 42 42 42 42 42 42 42 42 42 42 42 42 42 42 42 42 42 42 42 42 42 60 45
45 45 42 42 42 42 42 42 42 42 42 42 42 42 42 42 42 42 42 42 42 42 42 42 42 42 42 42 42 42 42 42 42 42 60 45
45 45 42 42 42 42 42 42 42 42 42 42 42 42 42 42 42 42 42 42 42 42 42 42 42 42 42 42 42 42 42 42 42 42 60 45
45 45 42 42 42 42 42 42 42 42 42 42 42 42 42 42 42 42 42 42 42 42 42 42 42 42 42 42 42 42 42 42 42 42 60 45
60 45 42 42 42 42 42 42 42 42 42 42 42 42 42 42 42 42 42 42 42 42 42 42 42 42 42 42 42 42 42 42 42 42 60 60
95 60 45 45 45 45 45 45 45 45 45 45 45 45 45 45 45 45 45 45 45 45 45 45 45 45 45 45 45 45 45 45 45 45 60 75
95 60 42 42 42 42 42 42 42 42 42 42 42 42 42 42 42 42 42 42 42 42 42 42 42 42 42 42 42 42 42 42 42 60 75 45>;
	synaptics,pt05_gap_y_c_ical = /bits/ 16 <
95 60 45 45 45 45 45 45 45 45 45 45 45 45 45 45 45 45 45 45 45 45 45 45 45 45 45 45 45 45 45 45 45 45 95 95
75 45 42 42 42 42 42 42 42 42 42 42 42 42 42 42 42 42 42 42 42 42 42 42 42 42 42 42 42 42 42 42 42 42 75 75
45 45 42 42 42 42 42 42 42 42 42 42 42 42 42 42 42 42 42 42 42 42 42 42 42 42 42 42 42 42 42 42 42 42 60 45
45 45 42 42 42 42 42 42 42 42 42 42 42 42 42 42 42 42 42 42 42 42 42 42 42 42 42 42 42 42 42 42 42 42 60 45
45 45 42 42 42 42 42 42 42 42 42 42 42 42 42 42 42 42 42 42 42 42 42 42 42 42 42 42 42 42 42 42 42 42 60 45
45 45 42 42 42 42 42 42 42 42 42 42 42 42 42 42 42 42 42 42 42 42 42 42 42 42 42 42 42 42 42 42 42 42 60 45
45 60 42 42 42 42 42 42 42 42 42 42 42 42 42 42 42 42 42 42 42 42 42 42 42 42 42 42 42 42 42 42 42 42 60 45
60 60 42 42 42 42 42 42 42 42 42 42 42 42 42 42 42 42 42 42 42 42 42 42 42 42 42 42 42 42 42 42 42 42 60 45
60 60 42 42 42 42 42 42 42 42 42 42 42 42 42 42 42 42 42 42 42 42 42 42 42 42 42 42 42 42 42 42 42 42 60 45
45 45 42 42 42 42 42 42 42 42 42 42 42 42 42 42 42 42 42 42 42 42 42 42 42 42 42 42 42 42 42 42 42 42 60 45
45 45 42 42 42 42 42 42 42 42 42 42 42 42 42 42 42 42 42 42 42 42 42 42 42 42 42 42 42 42 42 42 42 42 60 45
45 45 42 42 42 42 42 42 42 42 42 42 42 42 42 42 42 42 42 42 42 42 42 42 42 42 42 42 42 42 42 42 42 42 60 45
45 45 42 42 42 42 42 42 42 42 42 42 42 42 42 42 42 42 42 42 42 42 42 42 42 42 42 42 42 42 42 42 42 42 60 45
60 45 42 42 42 42 42 42 42 42 42 42 42 42 42 42 42 42 42 42 42 42 42 42 42 42 42 42 42 42 42 42 42 42 60 60
95 60 45 45 45 45 45 45 45 45 45 45 45 45 45 45 45 45 45 45 45 45 45 45 45 45 45 45 45 45 45 45 45 45 60 75
95 60 42 42 42 42 42 42 42 42 42 42 42 42 42 42 42 42 42 42 42 42 42 42 42 42 42 42 42 42 42 42 42 60 75 45>;

	synaptics,pt12_high_c_ical = <
312000 312000 312000 312000 312000 312000 312000 312000 312000 312000 312000 312000 312000 312000 312000 312000 312000 312000 312000 312000 312000 312000 312000 312000 312000 312000 312000 312000 312000 312000 312000 312000 312000 312000 312000 312000 456000 456000 456000 456000 456000 456000 456000 456000 456000 456000 456000 456000 456000 456000 456000 456000>;
	synaptics,pt12_low_c_ical = <
128000 128000 128000 128000 128000 128000 128000 128000 128000 128000 128000 128000 128000 128000 128000 128000 128000 128000 128000 128000 128000 128000 128000 128000 128000 128000 128000 128000 128000 128000 128000 128000 128000 128000 128000 128000 216000 216000 216000 216000 216000 216000 216000 216000 216000 216000 216000 216000 216000 216000 216000 216000>;

	controller-data {
		samsung,spi-feedback-delay = <0>;
		samsung,spi-chip-select-mode = <0>;
		cs-clock-delay = <2>;
	};

};

&google_gs_ct3c {
	touch = <&outer_touch>;
};

&google_gs_ct3d {
	touch = <&outer_touch>;
};

&google_gs_ct3e {
	touch = <&outer_touch>;
};
